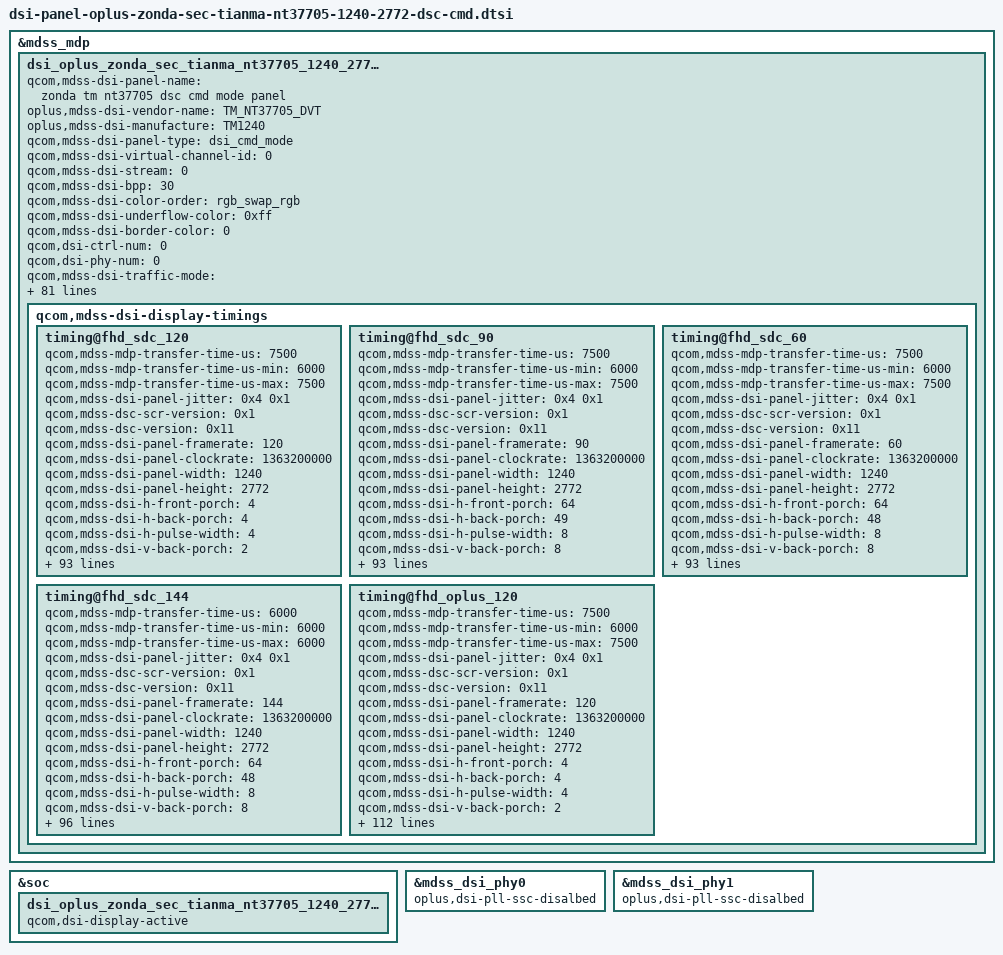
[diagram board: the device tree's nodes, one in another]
&mdss_mdp {
	dsi_oplus_zonda_sec_tianma_nt37705_1240_2772_dsc_cmd: qcom,mdss_dsi_oplus_zonda_sec_tianma_nt37705_1240_2772_dsc_cmd {
		qcom,mdss-dsi-panel-name = "zonda tm nt37705 dsc cmd mode panel";
		oplus,mdss-dsi-vendor-name = "TM_NT37705_DVT";
		oplus,mdss-dsi-manufacture = "TM1240";
		qcom,mdss-dsi-panel-type = "dsi_cmd_mode";
		qcom,mdss-dsi-virtual-channel-id = <0>;
		qcom,mdss-dsi-stream = <0>;
		qcom,mdss-dsi-bpp = <30>;
		qcom,mdss-dsi-color-order = "rgb_swap_rgb";
		qcom,mdss-dsi-underflow-color = <0xff>;
		qcom,mdss-dsi-border-color = <0>;
		qcom,dsi-ctrl-num = <0>;
		qcom,dsi-phy-num = <0>;
		qcom,mdss-dsi-traffic-mode = "non_burst_sync_event";
		qcom,mdss-dsi-lane-map = "lane_map_0123";
		qcom,mdss-dsi-bllp-eof-power-mode;
		qcom,mdss-dsi-bllp-power-mode;
		qcom,mdss-dsi-lane-0-state;
		qcom,mdss-dsi-lane-1-state;
		qcom,mdss-dsi-lane-2-state;
		qcom,mdss-dsi-lane-3-state;
		qcom,mdss-dsi-dma-trigger = "trigger_sw";
		qcom,mdss-dsi-mdp-trigger = "none";
		qcom,mdss-dsi-reset-sequence = <1 2>, <0 2>, <1 20>;

		qcom,mdss-dsi-te-pin-select = <1>;
		qcom,mdss-dsi-te-dcs-command = <1>;
		qcom,mdss-dsi-te-check-enable;
		qcom,mdss-dsi-te-using-te-pin;
		qcom,mdss-dsi-lp11-init;
		qcom,mdss-dsi-wr-mem-start = <0x2c>;
		qcom,mdss-dsi-wr-mem-continue = <0x3c>;
		/* HDR Setting */
		qcom,mdss-dsi-panel-hdr-enabled;
		qcom,mdss-dsi-panel-hdr-color-primaries = <15635 16450 34000 16000 13250 34500 7500 3000>;
		qcom,mdss-dsi-panel-peak-brightness = <5400000>;
		qcom,mdss-dsi-panel-blackness-level = <2000>;
		qcom,mdss-pan-physical-width-dimension = <70>;
		qcom,mdss-pan-physical-height-dimension = <156>;

		qcom,esd-check-enabled;
		//oplus,esd-check-flag-enabled;
		qcom,mdss-dsi-panel-status-check-mode = "reg_read";
		qcom,mdss-dsi-panel-status-command = [
				06 01 00 01 05 00 02 0A 00
			];
		qcom,mdss-dsi-panel-status-command-state = "dsi_lp_mode";
		qcom,mdss-dsi-panel-status-value = <0x9C>;
		qcom,mdss-dsi-panel-status-read-length = <1>;

		qcom,dynamic-mode-switch-enabled;
		qcom,dynamic-mode-switch-type = "dynamic-resolution-switch-immediate";
		qcom,mdss-dsi-display-timings {
				timing@fhd_sdc_120{
				qcom,mdss-mdp-transfer-time-us = <7500>;
				qcom,mdss-mdp-transfer-time-us-min = <6000>;
				qcom,mdss-mdp-transfer-time-us-max = <7500>;
				qcom,mdss-dsi-panel-jitter = <0x4 0x1>;
				qcom,mdss-dsc-scr-version = <0x1>;
				qcom,mdss-dsc-version = <0x11>;
				qcom,mdss-dsi-panel-framerate = <120>;
				qcom,mdss-dsi-panel-clockrate = <1363200000>;
				qcom,mdss-dsi-panel-width = <1240>;
				qcom,mdss-dsi-panel-height = <2772>;

				qcom,mdss-dsi-h-front-porch = <4>;
				qcom,mdss-dsi-h-back-porch = <4>;
				qcom,mdss-dsi-h-pulse-width = <4>;
				qcom,mdss-dsi-v-back-porch = <2>;
				qcom,mdss-dsi-v-front-porch = <2>;
				qcom,mdss-dsi-v-pulse-width = <2>;
				qcom,mdss-dsi-h-sync-pulse = <0>;

				qcom,mdss-dsi-h-left-border = <0>;
				qcom,mdss-dsi-h-right-border = <0>;
				qcom,mdss-dsi-v-top-border = <0>;
				qcom,mdss-dsi-v-bottom-border = <0>;

				/* Apollo vsync config, need to measure TE signal */
				//oplus,apollo-panel-vsync-width = <13000>;
				//oplus,apollo-panel-vsync-period = <16600>;

				/*SDC ADFR*/
				qcom,mdss-dsi-h-sync-skew = <0>;
				qcom,mdss-dsi-panel-vsync-source = <1>;
				qcom,mdss-dsi-qsync-min-fps-0 = <1314>;
				oplus,fod-on-vblank = <0>;
				oplus,fod-off-vblank = <0>;
				oplus,ofp-need-to-filter-backlight-dim-icon;
				qcom,mdss-dsi-bl-demura1-command = [
					/* 51hex > 0x644 */
					39 00 00 50 00 00 06 F0 55 AA 52 08 04
					39 00 00 50 00 00 02 6F 02
					39 00 00 50 00 00 03 EC 01 03
					39 00 00 50 00 00 02 6F A5
					39 00 00 10 00 00 07 EC 01 01 01 03 03 03
				];
				qcom,mdss-dsi-bl-demura2-command = [
					/* 0x644>51hex>=0x530 */
					39 00 00 50 00 00 06 F0 55 AA 52 08 04
					39 00 00 50 00 00 02 6F 02
					39 00 00 50 00 00 03 EC 03 0B
					39 00 00 50 00 00 02 6F A5
					39 00 00 10 00 00 07 EC 03 03 03 0B 0B 0B
				];
				qcom,mdss-dsi-bl-demura3-command = [
					/* 0x530>51hex>=0x33A */
					39 00 00 50 00 00 06 F0 55 AA 52 08 04
					39 00 00 50 00 00 02 6F 02
					39 00 00 50 00 00 03 EC 10 18
					39 00 00 50 00 00 02 6F A5
					39 00 00 10 00 00 07 EC 10 10 10 18 18 18
				];
				qcom,mdss-dsi-bl-demura4-command = [
					/* 0x339>51hex>=0x25C */
					39 00 00 50 00 00 06 F0 55 AA 52 08 04
					39 00 00 50 00 00 02 6F 02
					39 00 00 50 00 00 03 EC 15 1D
					39 00 00 50 00 00 02 6F A5
					39 00 00 10 00 00 07 EC 15 15 15 1D 1D 1D
				];
				qcom,mdss-dsi-bl-demura5-command = [
					/* 0x25C>51hex>=0x196 */
					39 00 00 50 00 00 06 F0 55 AA 52 08 04
					39 00 00 50 00 00 02 6F 02
					39 00 00 50 00 00 03 EC 15 2D
					39 00 00 50 00 00 02 6F A5
					39 00 00 10 00 00 07 EC 15 15 15 2D 2D 2D
				];
				qcom,mdss-dsi-bl-demura6-command = [
					/* 0x196>51hex>=0x008 */
					39 00 00 50 00 00 06 F0 55 AA 52 08 04
					39 00 00 50 00 00 02 6F 02
					39 00 00 50 00 00 03 EC 15 4D
					39 00 00 50 00 00 02 6F A5
					39 00 00 10 00 00 07 EC 15 15 15 4D 4D 4D
				];
				qcom,mdss-dsi-skipframe-dbv-command = [
					39 00 00 40 00 00 06 F0 55 AA 52 08 01
					39 00 00 40 00 00 02 6F 02
					39 00 00 40 00 00 11 E5 00 00 00 00 00 00 00 00 00 00 00 00 00 00 00 00
					39 00 00 40 00 00 02 6F 24
					39 00 00 40 00 00 0D E5 00 00 00 00 00 00 00 00 00 00 00 00
					39 00 00 40 00 00 02 6F 46
					39 00 00 40 00 00 0D E5 00 00 00 00 00 00 00 00 00 00 00 00
					39 00 00 40 00 00 02 6F 03
					39 00 00 40 00 00 19 C6 16 16 1F 23 23 23 23 23 23 23 23 21 23 23 23 23 23 23 18 18 21 23 23 23
					39 00 00 40 00 00 02 E5 B2
					39 00 00 40 00 00 02 6F 22
					39 00 00 40 00 00 02 E5 B2
					39 00 00 40 00 00 02 6F 44
					39 00 00 40 00 00 02 E5 B2
					39 00 00 40 00 00 06 F0 55 AA 52 08 05
					39 00 00 40 00 00 02 6F 12
					39 00 00 40 00 00 05 EC 00 00 00 00
					39 00 00 40 00 00 06 F0 55 AA 52 08 00
					39 00 00 40 00 00 02 6F 11
					39 00 00 40 00 00 04 B2 02 03 42
					39 00 00 00 00 00 03 51 03 FF
					];
				qcom,mdss-dsi-timing-switch-command = [
					/* switch */
					39 00 00 40 00 00 06 F0 55 AA 52 08 00
					39 00 00 00 0C 00 02 2F 00
					39 00 00 40 00 00 02 BE 47
					39 00 00 40 00 00 02 6F A8
					39 00 00 40 00 00 03 BA 00 00
					39 00 00 40 00 00 02 6F B0
					39 00 00 40 00 00 05 BA 00 00 00 00
					39 00 00 40 00 00 02 2F 30
					39 00 00 40 00 00 02 6D 00
					39 00 00 00 00 00 05 35 00 00 00 00
					];
				qcom,mdss-dsi-on-command=[
					/*Skip frame*/
					39 00 00 40 00 00 06 F0 55 AA 52 08 00
					39 00 00 40 00 00 02 6F 1B
					39 00 00 40 00 00 02 BA 18
					39 00 00 40 00 00 02 6F 1C
					39 00 00 40 00 00 11 BA 01 01 01 01 00 01 02 03 00 01 02 03 00 00 00 00
					39 00 00 40 00 00 02 6F 2C
					39 00 00 40 00 00 11 BA 01 01 01 01 00 01 02 03 00 01 02 03 00 00 00 00
					39 00 00 40 00 00 02 6F 3C
					39 00 00 40 00 00 11 BA 01 01 01 01 00 01 02 03 00 01 02 03 00 00 00 00
					39 00 00 40 00 00 02 6F 4C
					39 00 00 40 00 00 11 BA 01 01 01 01 00 01 02 03 00 01 02 03 00 00 00 00
					39 00 00 40 00 00 02 6F 5C
					39 00 00 40 00 00 05 BA 01 01 01 01
					39 00 00 40 00 00 02 6F 6C
					39 00 00 40 00 00 05 BA 00 01 02 03
					39 00 00 40 00 00 02 6F 7C
					39 00 00 40 00 00 05 BA 00 01 02 03
					39 00 00 40 00 00 02 6F 8C
					39 00 00 40 00 00 05 BA 00 00 00 00
					39 00 00 40 00 00 02 6F 9C
					39 00 00 40 00 00 09 BA 11 11 11 11 11 11 11 11
					39 00 00 40 00 00 02 6F A4
					39 00 00 40 00 00 03 BA E4 E4
					39 00 00 40 00 00 02 6F A8
					39 00 00 40 00 00 04 BA 00 00 00
					39 00 00 40 00 00 02 6F B0
					39 00 00 40 00 00 05 BA 00 00 00 00
					39 00 00 40 00 00 02 6F 08
					39 00 00 40 00 00 17 BB 01 00 00 00 01 00 00 00 01 00 00 00 01 00 00 00 01 00 00 00 00 00
					39 00 00 40 00 00 06 F0 55 AA 52 08 01
					39 00 00 40 00 00 13 E5 B2 22 00 00 00 00 20 20 20 20 24 24 24 24 00 00 00 00
					39 00 00 40 00 00 02 6F 22
					39 00 00 40 00 00 13 E5 B2 22 00 00 00 00 20 20 20 20 24 24 24 24 00 00 00 00
					39 00 00 40 00 00 02 6F 44
					39 00 00 40 00 00 13 E5 B2 22 00 00 00 00 20 20 20 20 24 24 24 24 00 00 00 00
					39 00 00 40 00 00 02 6F 66
					39 00 00 40 00 00 13 E5 B2 22 00 00 00 00 20 20 20 20 24 24 24 24 00 00 00 00
					39 00 00 40 00 00 02 6F 0C
					39 00 00 40 00 00 03 CE 0D 11
					39 00 00 40 00 00 02 6F 27
					39 00 00 40 00 00 06 B9 AA AA AA 00 00
					39 00 00 40 00 00 02 6F 03
					39 00 00 40 00 00 07 C6 16 16 16 23 23 23
					39 00 00 40 00 00 02 6F 0C
					39 00 00 40 00 00 07 C6 16 16 16 23 23 23
					39 00 00 40 00 00 02 6F 15
					39 00 00 40 00 00 07 C6 16 16 16 23 23 23
					39 00 00 40 00 00 02 6F 1E
					39 00 00 40 00 00 07 C6 16 16 16 23 23 23
					39 00 00 40 00 00 06 F0 55 AA 52 08 00
					39 00 00 40 00 00 02 6F 13
					39 00 00 40 00 00 02 C2 D8
					39 00 00 40 00 00 06 F0 55 AA 52 08 05
					39 00 00 40 00 00 02 6F 12
					39 00 00 40 00 00 05 EC 00 00 00 00
					/* Optimize edge green */
					/*39 00 00 40 00 00 06 F0 55 AA 52 08 07*/
					/*39 00 00 40 00 00 0E B4 C0 80 80 80 80 50 80 80 80 80 80 50 80*/
					/* Vsync Hsync output */
					39 00 00 40 00 00 06 F0 55 AA 52 08 00
					39 00 00 40 00 00 02 6F 02
					39 00 00 00 00 00 03 BE 49 4C
					/* AVDD=7.9 */
					/* 39 00 00 40 00 00 06 F0 55 AA 52 08 00 */
					/* 39 00 00 40 00 00 02 6F 07 */
					/* 39 00 00 40 00 00 02 B5 4E */
					/* HBM L0 glows green */
					39 00 00 40 00 00 02 B5 80
					39 00 00 40 00 00 02 6F 2C
					39 00 00 00 00 00 02 B5 03
					39 00 00 40 00 00 05 FF AA 55 A5 81
					39 00 00 40 00 00 02 6F 19
					39 00 00 40 00 00 02 FB 00
					39 00 00 40 00 00 02 6F 05
					39 00 00 40 00 00 02 FE 34
					39 00 00 40 00 00 05 FF AA 55 A5 80
					39 00 00 40 00 00 02 6F 1A
					39 00 00 40 00 00 02 F4 55
					39 00 00 40 00 00 05 FF AA 55 A5 83
					39 00 00 40 00 00 02 6F 12
					39 00 00 40 00 00 02 FE 41
					39 00 00 40 00 00 02 5F 00
					39 00 00 40 00 00 02 26 00
					39 00 00 40 00 00 02 26 00
					39 00 00 40 00 00 02 17 10
					39 00 00 40 00 00 05 2A 00 00 04 D7
					39 00 00 00 00 00 05 2B 00 00 0A D3
					/* Fre 120Hz */
					39 00 00 00 00 00 02 2F 00
					/* TE ON */
					39 00 00 40 00 00 02 35 00
					39 00 00 00 00 00 03 44 00 00
					/* Nor 51 */
					39 00 00 40 00 00 03 51 00 00
					39 00 00 00 00 00 02 6F 04
					/* AOD 51 */
					39 00 00 40 00 00 03 51 00 00
					39 00 00 40 00 00 02 53 20
					39 00 00 00 00 00 03 90 03 03
					/* 10bit DSC */
					39 00 00 40 00 00 13 91 AB 28 00 0C F2 00 02 85 01 0F 00 08 0A E9 07 5F 10 F0
					39 00 00 40 00 00 05 FF AA 55 A5 81
					39 00 00 40 00 00 02 6F 24
					39 00 00 40 00 00 15 FB 00 03 04 55 77 77 77 99 9D 00 00 06 88 9A BB BC DE EF F0 11
					39 00 00 40 00 00 05 FF AA 55 A5 81
					39 00 00 40 00 00 02 6F 0E
					39 00 00 40 00 00 02 F5 00
					39 00 00 40 00 00 05 FF AA 55 A5 80
					39 00 00 40 00 00 02 6F 0F
					39 00 00 40 00 00 02 FC 00
					39 00 00 40 00 00 02 6F 09
					39 00 00 40 00 00 03 FC FC F0
					39 00 00 40 00 00 05 FF AA 55 A5 80
					39 00 00 40 00 00 02 6F 0A
					39 00 00 40 00 00 04 F6 70 70 70
					39 00 00 40 00 00 02 6F 0E
					39 00 00 00 00 00 02 F6 60
					/* OSC start */
					39 00 00 40 00 00 05 FF AA 55 A5 80
					39 00 00 40 00 00 02 6F 11
					/* OSC2 145Mhz */
					39 00 00 40 00 00 03 F8 01 8E
					39 00 00 40 00 00 02 6F 2D
					/* OSC1 121.9Mhz */
					39 00 00 40 00 00 03 F8 00 FC
					39 00 00 40 00 00 02 6F 01
					39 00 00 40 00 00 02 1F 06
					39 00 00 40 00 00 05 FF AA 55 A5 81
					39 00 00 40 00 00 02 6F 1E
					39 00 00 00 00 00 02 FB 0F
					/* OSC end */
					39 00 00 40 00 00 05 FF AA 55 A5 83
					39 00 00 40 00 00 02 6F 12
					39 00 00 40 00 00 02 FE 41
					39 00 00 40 00 00 05 FF AA 55 A5 80
					39 00 00 40 00 00 02 6F 19
					39 00 00 40 00 00 02 F2 00
					39 00 00 40 00 00 05 FF AA 55 A5 81
					39 00 00 40 00 00 02 6F 02
					39 00 00 40 00 00 02 F9 04
					39 00 00 40 00 00 02 5A 00
					/* AOD remove black frame */
					39 00 00 00 00 00 06 F0 55 AA 52 08 01
					39 00 00 00 00 00 06 D2 00 00 00 00 15
					15 00 00 00 00 00 02 6F 05
					39 00 00 00 00 00 04 D2 01 00 00
					15 00 00 00 00 00 02 6F 0E
					39 00 00 00 00 00 06 D2 02 00 10 05 88
					39 00 00 00 00 00 0B E4 80 00 00 00 00 00 00 00 00 33
					15 00 00 00 00 00 02 6F 0A
					39 00 00 00 00 00 07 E4 80 00 00 10 00 53
					/* AOD off splash */
					39 00 00 40 00 00 06 F0 55 AA 52 08 01
					39 00 00 40 00 00 02 6F 0E
					39 00 00 00 00 00 06 D2 02 00 10 05 82
					/* 11H sleep out */
					39 00 00 00 80 00 02 11 00
					39 00 00 40 00 00 06 F0 55 AA 52 08 00
					39 00 00 00 11 00 02 2F 00
					39 00 00 40 00 00 02 BE 47
					39 00 00 40 00 00 02 6F A8
					39 00 00 40 00 00 03 BA 00 00
					39 00 00 40 00 00 02 6F B0
					39 00 00 40 00 00 05 BA 00 00 00 00
					39 00 00 40 00 00 02 2F 30
					39 00 00 40 00 00 02 6D 00
					39 00 00 00 00 00 05 35 00 00 00 00
					05 00 00 00 00 00 01 29
					/* OSC Tracking for 60/90/120 fps */
					39 00 00 40 00 00 06 F0 55 AA 52 08 01
					39 00 00 00 11 00 2A C3 DD 06 22 15 F9 00 06 20 15 FF 00 03 E7 16 06 2B 1D 03 E7 16 06 2B 1D 03 E7 16 06 2B 1D 03 E7 16 06 2B 1D 03 E7 16 06 2B 1D
				];

				qcom,mdss-dsi-panel-info-switch-page-command = [
					/*read panel info switch page 01*/
					39 00 00 00 00 00 06 F0 55 AA 52 08 01
				];
				qcom,mdss-dsi-default-switch-page-command = [
					/*switch default page*/
					39 00 00 00 00 00 06 F0 55 AA 52 08 00
				];

				qcom,mdss-dsi-qsync-min-fps-0-command = [
					/* SDC Auto Off */
					15 00 00 40 00 00 02 2F 00
					15 00 00 40 00 00 02 2F 30
					15 00 00 00 00 00 02 6D 00
				];

				qcom,mdss-dsi-post-on-backlight = [
					/* Display On */
					05 00 00 00 00 00 01 29
				];
				qcom,mdss-dsi-off-command=[
					05 00 00 00 0A 00 01 28
					05 00 00 00 78 00 01 10
				];
				qcom,mdss-dsi-lp1-command = [
					/* AOD Mode ON Setting */
					39 00 00 00 00 00 06 F0 55 AA 52 08 00
					15 00 00 00 00 00 02 6F 0C
					39 00 00 00 00 00 03 B5 50 4B
					39 00 00 00 00 00 05 35 00 00 00 00
					39 00 00 00 00 00 03 44 00 00
					15 00 00 00 00 00 02 2F 00
					05 00 00 00 00 00 01 39
					15 00 00 00 00 00 02 65 01
					15 00 00 00 00 00 02 6F 04
					39 00 00 00 00 00 03 51 02 FF
				];
				qcom,mdss-dsi-nolp-command = [
					/* AOD OFF */
					39 00 00 00 00 00 06 F0 55 AA 52 08 00
					15 00 00 00 00 00 02 6F 0C
					39 00 00 00 00 00 03 B5 4F 4B
					15 00 00 00 00 00 02 65 00
					05 00 00 00 00 00 01 38
					15 00 00 00 00 00 02 2F 30
					15 00 00 00 00 00 02 6D 00
					39 00 00 00 00 00 05 35 00 00 00 00
					39 00 00 00 00 00 03 44 00 00
					39 00 00 00 28 00 03 51 00 00
				];
				qcom,mdss-dsi-hbm-off-command = [
					//39 00 00 00 00 00 03 51 0D BB
				];
				qcom,mdss-dsi-hbm-on-command = [
					39 00 00 40 00 00 06 F0 55 AA 52 08 04
					39 00 00 40 00 00 02 6F 02
					39 00 00 40 00 00 03 EC 01 03
					39 00 00 40 00 00 02 6F A5
					39 00 00 00 00 00 07 EC 01 01 01 03 03 03
					39 00 00 40 00 00 06 F0 55 AA 52 08 01
					39 00 00 40 00 00 02 6F 02
					39 00 00 40 00 00 09 E5 00 00 00 00 20 20 20 00
					39 00 00 40 00 00 02 6F 46
					39 00 00 40 00 00 0D E5 00 00 00 00 20 20 20 00 28 28 28 00
					39 00 00 40 00 00 02 6F 03
					39 00 00 40 00 00 19 C6 37 37 37 23 23 23 23 23 23 23 23 23 23 23 23 23 23 23 37 37 37 23 23 23
					39 00 00 40 00 00 02 E5 B2
					39 00 00 40 00 00 02 6F 44
					39 00 00 40 00 00 02 E5 B2
					39 00 00 40 00 00 06 F0 55 AA 52 08 05
					39 00 00 40 00 00 02 6F 12
					39 00 00 40 00 00 05 EC 00 00 00 00
					39 00 00 40 00 00 06 F0 55 AA 52 08 00
					39 00 00 40 00 00 02 6F 11
					39 00 00 40 00 00 04 B2 02 03 42
					39 00 00 00 00 00 03 51 0F 00
				];
				qcom,mdss-dsi-aod-high-mode-command = [
					/* AOD 50nit */
					15 00 00 40 00 00 02 6F 04
					39 00 00 00 00 00 03 51 02 FF
				];
				qcom,mdss-dsi-aod-low-mode-command = [
					/* AOD 10nit */
					15 00 00 40 00 00 02 6F 04
					39 00 00 00 00 00 03 51 01 FF
				];
				qcom,mdss-dsi-timing-switch-command-state = "dsi_hs_mode";
				qcom,mdss-dsi-on-command-state = "dsi_lp_mode";
				qcom,mdss-dsi-off-command-state = "dsi_hs_mode";
				qcom,mdss-dsi-hbm-on-command-state = "dsi_lp_mode";
				qcom,mdss-dsi-hbm-off-command-state = "dsi_lp_mode";
				qcom,mdss-dsi-skipframe-dbv-command-state = "dsi_hs_mode";
				qcom,mdss-dsi-qsync-min-fps-0-command-state = "dsi_hs_mode";
				qcom,mdss-dsi-bl-demura1-command-state = "dsi_hs_mode";
				qcom,mdss-dsi-bl-demura2-command-state = "dsi_hs_mode";
				qcom,mdss-dsi-bl-demura3-command-state = "dsi_hs_mode";
				qcom,mdss-dsi-bl-demura4-command-state = "dsi_hs_mode";
				qcom,mdss-dsi-bl-demura5-command-state = "dsi_hs_mode";
				qcom,mdss-dsi-bl-demura6-command-state = "dsi_hs_mode";
				qcom,mdss-dsi-panel-info-switch-page-command-state = "dsi_lp_mode";
				qcom,mdss-dsi-default-switch-page-command-state = "dsi_lp_mode";

				qcom,lm-split = <620 620>;
				qcom,compression-mode = "dsc";
				qcom,mdss-dsc-encoders = <2>;
				qcom,mdss-dsc-slice-height = <12>;
				qcom,mdss-dsc-slice-width = <620>;
				qcom,mdss-dsc-slice-per-pkt = <2>;
				qcom,mdss-dsc-bit-per-component = <10>;
				qcom,mdss-dsc-bit-per-pixel = <8>;
				qcom,mdss-dsc-block-prediction-enable;
			};
			timing@fhd_sdc_90{
				qcom,mdss-mdp-transfer-time-us = <7500>;
				qcom,mdss-mdp-transfer-time-us-min = <6000>;
				qcom,mdss-mdp-transfer-time-us-max = <7500>;
				qcom,mdss-dsi-panel-jitter = <0x4 0x1>;
				qcom,mdss-dsc-scr-version = <0x1>;
				qcom,mdss-dsc-version = <0x11>;
				qcom,mdss-dsi-panel-framerate = <90>;
				qcom,mdss-dsi-panel-clockrate = <1363200000>;
				qcom,mdss-dsi-panel-width = <1240>;
				qcom,mdss-dsi-panel-height = <2772>;

				qcom,mdss-dsi-h-front-porch = <64>;
				qcom,mdss-dsi-h-back-porch = <49>;
				qcom,mdss-dsi-h-pulse-width = <8>;
				qcom,mdss-dsi-v-back-porch = <8>;
				qcom,mdss-dsi-v-front-porch = <2>;
				qcom,mdss-dsi-v-pulse-width = <2>;
				qcom,mdss-dsi-h-sync-pulse = <0>;

				qcom,mdss-dsi-h-left-border = <0>;
				qcom,mdss-dsi-h-right-border = <0>;
				qcom,mdss-dsi-v-top-border = <0>;
				qcom,mdss-dsi-v-bottom-border = <0>;

				/* Apollo vsync config, need to measure TE signal */
				//oplus,apollo-panel-vsync-width = <13000>;
				//oplus,apollo-panel-vsync-period = <16600>;

				qcom,mdss-dsi-h-sync-skew = <0>;
				qcom,mdss-dsi-panel-vsync-source = <1>;
				qcom,mdss-dsi-qsync-min-fps-0 = <1314>;
				oplus,fod-on-vblank = <0>;
				oplus,fod-off-vblank = <0>;
				oplus,ofp-need-to-filter-backlight-dim-icon;
				qcom,mdss-dsi-bl-demura1-command = [
					/* 51hex > 0x644 */
					39 00 00 50 00 00 06 F0 55 AA 52 08 04
					39 00 00 50 00 00 02 6F 02
					39 00 00 50 00 00 03 EC 01 03
					39 00 00 50 00 00 02 6F A5
					39 00 00 10 00 00 07 EC 01 01 01 03 03 03
				];
				qcom,mdss-dsi-bl-demura2-command = [
					/* 0x644>51hex>=0x530 */
					39 00 00 50 00 00 06 F0 55 AA 52 08 04
					39 00 00 50 00 00 02 6F 02
					39 00 00 50 00 00 03 EC 03 0B
					39 00 00 50 00 00 02 6F A5
					39 00 00 10 00 00 07 EC 03 03 03 0B 0B 0B
				];
				qcom,mdss-dsi-bl-demura3-command = [
					/* 0x530>51hex>=0x33A */
					39 00 00 50 00 00 06 F0 55 AA 52 08 04
					39 00 00 50 00 00 02 6F 02
					39 00 00 50 00 00 03 EC 10 18
					39 00 00 50 00 00 02 6F A5
					39 00 00 10 00 00 07 EC 10 10 10 18 18 18
				];
				qcom,mdss-dsi-bl-demura4-command = [
					/* 0x339>51hex>=0x25C */
					39 00 00 50 00 00 06 F0 55 AA 52 08 04
					39 00 00 50 00 00 02 6F 02
					39 00 00 50 00 00 03 EC 15 1D
					39 00 00 50 00 00 02 6F A5
					39 00 00 10 00 00 07 EC 15 15 15 1D 1D 1D
				];
				qcom,mdss-dsi-bl-demura5-command = [
					/* 0x25C>51hex>=0x196 */
					39 00 00 50 00 00 06 F0 55 AA 52 08 04
					39 00 00 50 00 00 02 6F 02
					39 00 00 50 00 00 03 EC 15 2D
					39 00 00 50 00 00 02 6F A5
					39 00 00 10 00 00 07 EC 15 15 15 2D 2D 2D
				];
				qcom,mdss-dsi-bl-demura6-command = [
					/* 0x196>51hex>=0x008 */
					39 00 00 50 00 00 06 F0 55 AA 52 08 04
					39 00 00 50 00 00 02 6F 02
					39 00 00 50 00 00 03 EC 15 4D
					39 00 00 50 00 00 02 6F A5
					39 00 00 10 00 00 07 EC 15 15 15 4D 4D 4D
				];
				qcom,mdss-dsi-skipframe-dbv-command = [
					39 00 00 40 00 00 06 F0 55 AA 52 08 01
					39 00 00 40 00 00 02 6F 02
					39 00 00 40 00 00 11 E5 00 00 00 00 00 00 00 00 00 00 00 00 00 00 00 00
					39 00 00 40 00 00 02 6F 24
					39 00 00 40 00 00 0D E5 00 00 00 00 00 00 00 00 00 00 00 00
					39 00 00 40 00 00 02 6F 46
					39 00 00 40 00 00 0D E5 00 00 00 00 00 00 00 00 00 00 00 00
					39 00 00 40 00 00 02 6F 03
					39 00 00 40 00 00 19 C6 16 16 1F 23 23 23 23 23 23 23 23 21 23 23 23 23 23 23 18 18 21 23 23 23
					39 00 00 40 00 00 02 E5 B2
					39 00 00 40 00 00 02 6F 22
					39 00 00 40 00 00 02 E5 B2
					39 00 00 40 00 00 02 6F 44
					39 00 00 40 00 00 02 E5 B2
					39 00 00 40 00 00 06 F0 55 AA 52 08 05
					39 00 00 40 00 00 02 6F 12
					39 00 00 40 00 00 05 EC 00 00 00 00
					39 00 00 40 00 00 06 F0 55 AA 52 08 00
					39 00 00 40 00 00 02 6F 11
					39 00 00 40 00 00 04 B2 02 03 42
					39 00 00 00 00 00 03 51 03 FF
					];
				qcom,mdss-dsi-timing-switch-command = [
					/* switch */
					39 00 00 40 00 00 06 F0 55 AA 52 08 00
					39 00 00 00 0C 00 02 2F 01
					39 00 00 40 00 00 02 BE 47
					39 00 00 40 00 00 02 6F A8
					39 00 00 40 00 00 03 BA 11 11
					39 00 00 40 00 00 02 6F B0
					39 00 00 40 00 00 05 BA 11 11 00 00
					39 00 00 40 00 00 02 2F 31
					39 00 00 40 00 00 02 6D 00
					39 00 00 00 00 00 05 35 00 00 00 00
					];
				qcom,mdss-dsi-on-command=[
					/*Skip frame*/
					39 00 00 40 00 00 06 F0 55 AA 52 08 00
					39 00 00 40 00 00 02 6F 1B
					39 00 00 40 00 00 02 BA 18
					39 00 00 40 00 00 02 6F 1C
					39 00 00 40 00 00 11 BA 01 01 01 01 00 01 02 03 00 01 02 03 00 00 00 00
					39 00 00 40 00 00 02 6F 2C
					39 00 00 40 00 00 11 BA 01 01 01 01 00 01 02 03 00 01 02 03 00 00 00 00
					39 00 00 40 00 00 02 6F 3C
					39 00 00 40 00 00 11 BA 01 01 01 01 00 01 02 03 00 01 02 03 00 00 00 00
					39 00 00 40 00 00 02 6F 4C
					39 00 00 40 00 00 11 BA 01 01 01 01 00 01 02 03 00 01 02 03 00 00 00 00
					39 00 00 40 00 00 02 6F 5C
					39 00 00 40 00 00 05 BA 01 01 01 01
					39 00 00 40 00 00 02 6F 6C
					39 00 00 40 00 00 05 BA 00 01 02 03
					39 00 00 40 00 00 02 6F 7C
					39 00 00 40 00 00 05 BA 00 01 02 03
					39 00 00 40 00 00 02 6F 8C
					39 00 00 40 00 00 05 BA 00 00 00 00
					39 00 00 40 00 00 02 6F 9C
					39 00 00 40 00 00 09 BA 11 11 11 11 11 11 11 11
					39 00 00 40 00 00 02 6F A4
					39 00 00 40 00 00 03 BA E4 E4
					39 00 00 40 00 00 02 6F A8
					39 00 00 40 00 00 04 BA 00 00 00
					39 00 00 40 00 00 02 6F B0
					39 00 00 40 00 00 05 BA 00 00 00 00
					39 00 00 40 00 00 02 6F 08
					39 00 00 40 00 00 17 BB 01 00 00 00 01 00 00 00 01 00 00 00 01 00 00 00 01 00 00 00 00 00
					39 00 00 40 00 00 06 F0 55 AA 52 08 01
					39 00 00 40 00 00 13 E5 B2 22 00 00 00 00 20 20 20 20 24 24 24 24 00 00 00 00
					39 00 00 40 00 00 02 6F 22
					39 00 00 40 00 00 13 E5 B2 22 00 00 00 00 20 20 20 20 24 24 24 24 00 00 00 00
					39 00 00 40 00 00 02 6F 44
					39 00 00 40 00 00 13 E5 B2 22 00 00 00 00 20 20 20 20 24 24 24 24 00 00 00 00
					39 00 00 40 00 00 02 6F 66
					39 00 00 40 00 00 13 E5 B2 22 00 00 00 00 20 20 20 20 24 24 24 24 00 00 00 00
					39 00 00 40 00 00 02 6F 0C
					39 00 00 40 00 00 03 CE 0D 11
					39 00 00 40 00 00 02 6F 27
					39 00 00 40 00 00 06 B9 AA AA AA 00 00
					39 00 00 40 00 00 02 6F 03
					39 00 00 40 00 00 07 C6 16 16 16 23 23 23
					39 00 00 40 00 00 02 6F 0C
					39 00 00 40 00 00 07 C6 16 16 16 23 23 23
					39 00 00 40 00 00 02 6F 15
					39 00 00 40 00 00 07 C6 16 16 16 23 23 23
					39 00 00 40 00 00 02 6F 1E
					39 00 00 40 00 00 07 C6 16 16 16 23 23 23
					39 00 00 40 00 00 06 F0 55 AA 52 08 00
					39 00 00 40 00 00 02 6F 13
					39 00 00 40 00 00 02 C2 D8
					39 00 00 40 00 00 06 F0 55 AA 52 08 05
					39 00 00 40 00 00 02 6F 12
					39 00 00 40 00 00 05 EC 00 00 00 00
					/* Optimize edge green */
					/*39 00 00 40 00 00 06 F0 55 AA 52 08 07*/
					/*39 00 00 40 00 00 0E B4 C0 80 80 80 80 50 80 80 80 80 80 50 80*/
					/* Vsync Hsync output */
					39 00 00 40 00 00 06 F0 55 AA 52 08 00
					39 00 00 40 00 00 02 6F 02
					39 00 00 00 00 00 03 BE 49 4C
					/* AVDD=7.9 */
					/* 39 00 00 40 00 00 06 F0 55 AA 52 08 00 */
					/* 39 00 00 40 00 00 02 6F 07 */
					/* 39 00 00 40 00 00 02 B5 4E */
					/* HBM L0 glows green */
					39 00 00 40 00 00 02 B5 80
					39 00 00 40 00 00 02 6F 2C
					39 00 00 00 00 00 02 B5 03
					39 00 00 40 00 00 05 FF AA 55 A5 81
					39 00 00 40 00 00 02 6F 19
					39 00 00 40 00 00 02 FB 00
					39 00 00 40 00 00 02 6F 05
					39 00 00 40 00 00 02 FE 34
					39 00 00 40 00 00 05 FF AA 55 A5 80
					39 00 00 40 00 00 02 6F 1A
					39 00 00 40 00 00 02 F4 55
					39 00 00 40 00 00 05 FF AA 55 A5 83
					39 00 00 40 00 00 02 6F 12
					39 00 00 40 00 00 02 FE 41
					39 00 00 40 00 00 02 5F 00
					39 00 00 40 00 00 02 26 00
					39 00 00 40 00 00 02 26 00
					39 00 00 40 00 00 02 17 10
					39 00 00 40 00 00 05 2A 00 00 04 D7
					39 00 00 00 00 00 05 2B 00 00 0A D3
					/* Fre 90Hz */
					39 00 00 00 00 00 02 2F 01
					/* TE ON */
					39 00 00 40 00 00 02 35 00
					39 00 00 00 00 00 03 44 00 00
					/* Nor 51 */
					39 00 00 40 00 00 03 51 00 00
					39 00 00 00 00 00 02 6F 04
					/* AOD 51 */
					39 00 00 40 00 00 03 51 00 00
					39 00 00 40 00 00 02 53 20
					39 00 00 00 00 00 03 90 03 03
					/* 10bit DSC */
					39 00 00 40 00 00 13 91 AB 28 00 0C F2 00 02 85 01 0F 00 08 0A E9 07 5F 10 F0
					39 00 00 40 00 00 05 FF AA 55 A5 81
					39 00 00 40 00 00 02 6F 24
					39 00 00 40 00 00 15 FB 00 03 04 55 77 77 77 99 9D 00 00 06 88 9A BB BC DE EF F0 11
					39 00 00 40 00 00 05 FF AA 55 A5 81
					39 00 00 40 00 00 02 6F 0E
					39 00 00 40 00 00 02 F5 00
					39 00 00 40 00 00 05 FF AA 55 A5 80
					39 00 00 40 00 00 02 6F 0F
					39 00 00 40 00 00 02 FC 00
					39 00 00 40 00 00 02 6F 09
					39 00 00 40 00 00 03 FC FC F0
					39 00 00 40 00 00 05 FF AA 55 A5 80
					39 00 00 40 00 00 02 6F 0A
					39 00 00 40 00 00 04 F6 70 70 70
					39 00 00 40 00 00 02 6F 0E
					39 00 00 00 00 00 02 F6 60
					/* OSC start */
					39 00 00 40 00 00 05 FF AA 55 A5 80
					39 00 00 40 00 00 02 6F 11
					/* OSC2 145Mhz */
					39 00 00 40 00 00 03 F8 01 8E
					39 00 00 40 00 00 02 6F 2D
					/* OSC1 121.9Mhz */
					39 00 00 40 00 00 03 F8 00 FC
					39 00 00 40 00 00 02 6F 01
					39 00 00 40 00 00 02 1F 06
					39 00 00 40 00 00 05 FF AA 55 A5 81
					39 00 00 40 00 00 02 6F 1E
					39 00 00 00 00 00 02 FB 0F
					/* OSC end */
					39 00 00 40 00 00 05 FF AA 55 A5 83
					39 00 00 40 00 00 02 6F 12
					39 00 00 40 00 00 02 FE 41
					39 00 00 40 00 00 05 FF AA 55 A5 80
					39 00 00 40 00 00 02 6F 19
					39 00 00 40 00 00 02 F2 00
					39 00 00 40 00 00 05 FF AA 55 A5 81
					39 00 00 40 00 00 02 6F 02
					39 00 00 40 00 00 02 F9 04
					39 00 00 40 00 00 02 5A 00
					/* AOD remove black frame */
					39 00 00 00 00 00 06 F0 55 AA 52 08 01
					39 00 00 00 00 00 06 D2 00 00 00 00 15
					15 00 00 00 00 00 02 6F 05
					39 00 00 00 00 00 04 D2 01 00 00
					15 00 00 00 00 00 02 6F 0E
					39 00 00 00 00 00 06 D2 02 00 10 05 88
					39 00 00 00 00 00 0B E4 80 00 00 00 00 00 00 00 00 33
					15 00 00 00 00 00 02 6F 0A
					39 00 00 00 00 00 07 E4 80 00 00 10 00 53
					/* AOD off splash */
					39 00 00 40 00 00 06 F0 55 AA 52 08 01
					39 00 00 40 00 00 02 6F 0E
					39 00 00 00 00 00 06 D2 02 00 10 05 82
					/* 11H sleep out */
					39 00 00 00 80 00 02 11 00
					39 00 00 40 00 00 06 F0 55 AA 52 08 00
					39 00 00 00 0C 00 02 2F 01
					39 00 00 40 00 00 02 BE 47
					39 00 00 40 00 00 02 6F A8
					39 00 00 40 00 00 03 BA 11 11
					39 00 00 40 00 00 02 6F B0
					39 00 00 40 00 00 05 BA 11 11 00 00
					39 00 00 40 00 00 02 2F 31
					39 00 00 40 00 00 02 6D 00
					39 00 00 00 00 00 05 35 00 00 00 00
					05 00 00 00 00 00 01 29
					/* OSC Tracking for 60/90/120 fps */
					39 00 00 40 00 00 06 F0 55 AA 52 08 01
					39 00 00 00 11 00 2A C3 DD 06 22 15 F9 00 06 20 15 FF 00 03 E7 16 06 2B 1D 03 E7 16 06 2B 1D 03 E7 16 06 2B 1D 03 E7 16 06 2B 1D 03 E7 16 06 2B 1D
				];

				qcom,mdss-dsi-panel-info-switch-page-command = [
					/*read panel info switch page 01*/
					39 00 00 00 00 00 06 F0 55 AA 52 08 01
				];
				qcom,mdss-dsi-default-switch-page-command = [
					/*switch default page*/
					39 00 00 00 00 00 06 F0 55 AA 52 08 00
				];

				qcom,mdss-dsi-qsync-min-fps-0-command = [
					/* SDC Auto Off */
					15 00 00 40 00 00 02 2F 01
					15 00 00 40 00 00 02 2F 31
					15 00 00 00 00 00 02 6D 00
				];

				qcom,mdss-dsi-post-on-backlight = [
					/* Display On */
					05 00 00 00 00 00 01 29
				];
				qcom,mdss-dsi-off-command=[
					05 00 00 00 0A 00 01 28
					05 00 00 00 78 00 01 10
				];
				qcom,mdss-dsi-lp1-command = [
					/* AOD Mode ON Setting */
					39 00 00 00 00 00 06 F0 55 AA 52 08 00
					15 00 00 00 00 00 02 6F 0C
					39 00 00 00 00 00 03 B5 50 4B
					39 00 00 00 00 00 05 35 00 00 00 00
					39 00 00 00 00 00 03 44 00 00
					15 00 00 00 00 00 02 2F 00
					05 00 00 00 00 00 01 39
					15 00 00 00 00 00 02 65 01
					15 00 00 00 00 00 02 6F 04
					39 00 00 00 00 00 03 51 02 FF
				];
				qcom,mdss-dsi-nolp-command = [
					/* AOD OFF */
					39 00 00 00 00 00 06 F0 55 AA 52 08 00
					15 00 00 00 00 00 02 6F 0C
					39 00 00 00 00 00 03 B5 4F 4B
					15 00 00 00 00 00 02 65 00
					05 00 00 00 00 00 01 38
					15 00 00 00 00 00 02 2F 31
					15 00 00 00 00 00 02 6D 00
					39 00 00 00 00 00 05 35 00 00 00 00
					39 00 00 00 00 00 03 44 00 00
					39 00 00 00 28 00 03 51 00 00
				];
				qcom,mdss-dsi-hbm-off-command = [
					//39 00 00 00 00 00 03 51 0D BB
				];
				qcom,mdss-dsi-hbm-on-command = [
					39 00 00 40 00 00 06 F0 55 AA 52 08 04
					39 00 00 40 00 00 02 6F 02
					39 00 00 40 00 00 03 EC 01 03
					39 00 00 40 00 00 02 6F A5
					39 00 00 00 00 00 07 EC 01 01 01 03 03 03
					39 00 00 40 00 00 06 F0 55 AA 52 08 01
					39 00 00 40 00 00 02 6F 02
					39 00 00 40 00 00 09 E5 00 00 00 00 20 20 20 00
					39 00 00 40 00 00 02 6F 46
					39 00 00 40 00 00 0D E5 00 00 00 00 20 20 20 00 28 28 28 00
					39 00 00 40 00 00 02 6F 03
					39 00 00 40 00 00 19 C6 37 37 37 23 23 23 23 23 23 23 23 23 23 23 23 23 23 23 37 37 37 23 23 23
					39 00 00 40 00 00 02 E5 B2
					39 00 00 40 00 00 02 6F 44
					39 00 00 40 00 00 02 E5 B2
					39 00 00 40 00 00 06 F0 55 AA 52 08 05
					39 00 00 40 00 00 02 6F 12
					39 00 00 40 00 00 05 EC 00 00 00 00
					39 00 00 40 00 00 06 F0 55 AA 52 08 00
					39 00 00 40 00 00 02 6F 11
					39 00 00 40 00 00 04 B2 02 03 42
					39 00 00 00 00 00 03 51 0F 00
				];
				qcom,mdss-dsi-aod-high-mode-command = [
					/* AOD 50nit */
					15 00 00 40 00 00 02 6F 04
					39 00 00 00 00 00 03 51 02 FF
				];
				qcom,mdss-dsi-aod-low-mode-command = [
					/* AOD 10nit */
					15 00 00 40 00 00 02 6F 04
					39 00 00 00 00 00 03 51 01 FF
				];
				qcom,mdss-dsi-timing-switch-command-state = "dsi_hs_mode";
				qcom,mdss-dsi-on-command-state = "dsi_lp_mode";
				qcom,mdss-dsi-off-command-state = "dsi_hs_mode";
				qcom,mdss-dsi-hbm-on-command-state = "dsi_lp_mode";
				qcom,mdss-dsi-hbm-off-command-state = "dsi_lp_mode";
				qcom,mdss-dsi-skipframe-dbv-command-state = "dsi_hs_mode";
				qcom,mdss-dsi-qsync-min-fps-0-command-state = "dsi_hs_mode";
				qcom,mdss-dsi-bl-demura1-command-state = "dsi_hs_mode";
				qcom,mdss-dsi-bl-demura2-command-state = "dsi_hs_mode";
				qcom,mdss-dsi-bl-demura3-command-state = "dsi_hs_mode";
				qcom,mdss-dsi-bl-demura4-command-state = "dsi_hs_mode";
				qcom,mdss-dsi-bl-demura5-command-state = "dsi_hs_mode";
				qcom,mdss-dsi-bl-demura6-command-state = "dsi_hs_mode";
				qcom,mdss-dsi-panel-info-switch-page-command-state = "dsi_lp_mode";
				qcom,mdss-dsi-default-switch-page-command-state = "dsi_lp_mode";

				qcom,lm-split = <620 620>;
				qcom,compression-mode = "dsc";
				qcom,mdss-dsc-encoders = <2>;
				qcom,mdss-dsc-slice-height = <12>;
				qcom,mdss-dsc-slice-width = <620>;
				qcom,mdss-dsc-slice-per-pkt = <2>;
				qcom,mdss-dsc-bit-per-component = <10>;
				qcom,mdss-dsc-bit-per-pixel = <8>;
				qcom,mdss-dsc-block-prediction-enable;
			};
			timing@fhd_sdc_60{
				qcom,mdss-mdp-transfer-time-us = <7500>;
				qcom,mdss-mdp-transfer-time-us-min = <6000>;
				qcom,mdss-mdp-transfer-time-us-max = <7500>;
				qcom,mdss-dsi-panel-jitter = <0x4 0x1>;
				qcom,mdss-dsc-scr-version = <0x1>;
				qcom,mdss-dsc-version = <0x11>;
				qcom,mdss-dsi-panel-framerate = <60>;
				qcom,mdss-dsi-panel-clockrate = <1363200000>;
				qcom,mdss-dsi-panel-width = <1240>;
				qcom,mdss-dsi-panel-height = <2772>;

				qcom,mdss-dsi-h-front-porch = <64>;
				qcom,mdss-dsi-h-back-porch = <48>;
				qcom,mdss-dsi-h-pulse-width = <8>;
				qcom,mdss-dsi-v-back-porch = <8>;
				qcom,mdss-dsi-v-front-porch = <2>;
				qcom,mdss-dsi-v-pulse-width = <2>;
				qcom,mdss-dsi-h-sync-pulse = <0>;

				qcom,mdss-dsi-h-left-border = <0>;
				qcom,mdss-dsi-h-right-border = <0>;
				qcom,mdss-dsi-v-top-border = <0>;
				qcom,mdss-dsi-v-bottom-border = <0>;

				/* Apollo vsync config, need to measure TE signal */
				//oplus,apollo-panel-vsync-width = <13000>;
				//oplus,apollo-panel-vsync-period = <16600>;
				qcom,mdss-dsi-h-sync-skew = <0>;
				qcom,mdss-dsi-panel-vsync-source = <1>;
				qcom,mdss-dsi-qsync-min-fps-0 = <1314>;
				oplus,fod-on-vblank = <0>;
				oplus,fod-off-vblank = <0>;
				oplus,ofp-need-to-filter-backlight-dim-icon;
				qcom,mdss-dsi-bl-demura1-command = [
					/* 51hex > 0x644 */
					39 00 00 50 00 00 06 F0 55 AA 52 08 04
					39 00 00 50 00 00 02 6F 02
					39 00 00 50 00 00 03 EC 01 03
					39 00 00 50 00 00 02 6F A5
					39 00 00 10 00 00 07 EC 01 01 01 03 03 03
				];
				qcom,mdss-dsi-bl-demura2-command = [
					/* 0x644>51hex>=0x530 */
					39 00 00 50 00 00 06 F0 55 AA 52 08 04
					39 00 00 50 00 00 02 6F 02
					39 00 00 50 00 00 03 EC 03 0B
					39 00 00 50 00 00 02 6F A5
					39 00 00 10 00 00 07 EC 03 03 03 0B 0B 0B
				];
				qcom,mdss-dsi-bl-demura3-command = [
					/* 0x530>51hex>=0x33A */
					39 00 00 50 00 00 06 F0 55 AA 52 08 04
					39 00 00 50 00 00 02 6F 02
					39 00 00 50 00 00 03 EC 10 18
					39 00 00 50 00 00 02 6F A5
					39 00 00 10 00 00 07 EC 10 10 10 18 18 18
				];
				qcom,mdss-dsi-bl-demura4-command = [
					/* 0x339>51hex>=0x25C */
					39 00 00 50 00 00 06 F0 55 AA 52 08 04
					39 00 00 50 00 00 02 6F 02
					39 00 00 50 00 00 03 EC 15 1D
					39 00 00 50 00 00 02 6F A5
					39 00 00 10 00 00 07 EC 15 15 15 1D 1D 1D
				];
				qcom,mdss-dsi-bl-demura5-command = [
					/* 0x25C>51hex>=0x196 */
					39 00 00 50 00 00 06 F0 55 AA 52 08 04
					39 00 00 50 00 00 02 6F 02
					39 00 00 50 00 00 03 EC 15 2D
					39 00 00 50 00 00 02 6F A5
					39 00 00 10 00 00 07 EC 15 15 15 2D 2D 2D
				];
				qcom,mdss-dsi-bl-demura6-command = [
					/* 0x196>51hex>=0x008 */
					39 00 00 50 00 00 06 F0 55 AA 52 08 04
					39 00 00 50 00 00 02 6F 02
					39 00 00 50 00 00 03 EC 15 4D
					39 00 00 50 00 00 02 6F A5
					39 00 00 10 00 00 07 EC 15 15 15 4D 4D 4D
				];
				qcom,mdss-dsi-skipframe-dbv-command = [
					39 00 00 40 00 00 06 F0 55 AA 52 08 01
					39 00 00 40 00 00 02 6F 02
					39 00 00 40 00 00 11 E5 00 00 00 00 00 00 00 00 00 00 00 00 00 00 00 00
					39 00 00 40 00 00 02 6F 24
					39 00 00 40 00 00 0D E5 00 00 00 00 00 00 00 00 00 00 00 00
					39 00 00 40 00 00 02 6F 46
					39 00 00 40 00 00 0D E5 00 00 00 00 00 00 00 00 00 00 00 00
					39 00 00 40 00 00 02 6F 03
					39 00 00 40 00 00 19 C6 16 16 1F 23 23 23 23 23 23 23 23 21 23 23 23 23 23 23 18 18 21 23 23 23
					39 00 00 40 00 00 02 E5 B2
					39 00 00 40 00 00 02 6F 22
					39 00 00 40 00 00 02 E5 B2
					39 00 00 40 00 00 02 6F 44
					39 00 00 40 00 00 02 E5 B2
					39 00 00 40 00 00 06 F0 55 AA 52 08 05
					39 00 00 40 00 00 02 6F 12
					39 00 00 40 00 00 05 EC 00 00 00 00
					39 00 00 40 00 00 06 F0 55 AA 52 08 00
					39 00 00 40 00 00 02 6F 11
					39 00 00 40 00 00 04 B2 02 03 42
					39 00 00 00 00 00 03 51 03 FF
					];
				qcom,mdss-dsi-timing-switch-command = [
					/* switch60Hz */
					39 00 00 40 00 00 06 F0 55 AA 52 08 00
					39 00 00 00 11 00 02 2F 00
					39 00 00 40 00 00 02 6F A8
					39 00 00 40 00 00 03 BA 00 00
					39 00 00 40 00 00 02 6F B0
					39 00 00 40 00 00 05 BA 00 00 00 00
					39 00 00 40 00 00 02 2F 30
					39 00 00 40 00 00 02 6D 01
					39 00 00 00 00 00 05 35 00 00 00 01
					];
				qcom,mdss-dsi-on-command=[
					/*Skip frame*/
					39 00 00 40 00 00 06 F0 55 AA 52 08 00
					39 00 00 40 00 00 02 6F 1B
					39 00 00 40 00 00 02 BA 18
					39 00 00 40 00 00 02 6F 1C
					39 00 00 40 00 00 11 BA 01 01 01 01 00 01 02 03 00 01 02 03 00 00 00 00
					39 00 00 40 00 00 02 6F 2C
					39 00 00 40 00 00 11 BA 01 01 01 01 00 01 02 03 00 01 02 03 00 00 00 00
					39 00 00 40 00 00 02 6F 3C
					39 00 00 40 00 00 11 BA 01 01 01 01 00 01 02 03 00 01 02 03 00 00 00 00
					39 00 00 40 00 00 02 6F 4C
					39 00 00 40 00 00 11 BA 01 01 01 01 00 01 02 03 00 01 02 03 00 00 00 00
					39 00 00 40 00 00 02 6F 5C
					39 00 00 40 00 00 05 BA 01 01 01 01
					39 00 00 40 00 00 02 6F 6C
					39 00 00 40 00 00 05 BA 00 01 02 03
					39 00 00 40 00 00 02 6F 7C
					39 00 00 40 00 00 05 BA 00 01 02 03
					39 00 00 40 00 00 02 6F 8C
					39 00 00 40 00 00 05 BA 00 00 00 00
					39 00 00 40 00 00 02 6F 9C
					39 00 00 40 00 00 09 BA 11 11 11 11 11 11 11 11
					39 00 00 40 00 00 02 6F A4
					39 00 00 40 00 00 03 BA E4 E4
					39 00 00 40 00 00 02 6F A8
					39 00 00 40 00 00 04 BA 00 00 00
					39 00 00 40 00 00 02 6F B0
					39 00 00 40 00 00 05 BA 00 00 00 00
					39 00 00 40 00 00 02 6F 08
					39 00 00 40 00 00 17 BB 01 00 00 00 01 00 00 00 01 00 00 00 01 00 00 00 01 00 00 00 00 00
					39 00 00 40 00 00 06 F0 55 AA 52 08 01
					39 00 00 40 00 00 13 E5 B2 22 00 00 00 00 20 20 20 20 24 24 24 24 00 00 00 00
					39 00 00 40 00 00 02 6F 22
					39 00 00 40 00 00 13 E5 B2 22 00 00 00 00 20 20 20 20 24 24 24 24 00 00 00 00
					39 00 00 40 00 00 02 6F 44
					39 00 00 40 00 00 13 E5 B2 22 00 00 00 00 20 20 20 20 24 24 24 24 00 00 00 00
					39 00 00 40 00 00 02 6F 66
					39 00 00 40 00 00 13 E5 B2 22 00 00 00 00 20 20 20 20 24 24 24 24 00 00 00 00
					39 00 00 40 00 00 02 6F 0C
					39 00 00 40 00 00 03 CE 0D 11
					39 00 00 40 00 00 02 6F 27
					39 00 00 40 00 00 06 B9 AA AA AA 00 00
					39 00 00 40 00 00 02 6F 03
					39 00 00 40 00 00 07 C6 16 16 16 23 23 23
					39 00 00 40 00 00 02 6F 0C
					39 00 00 40 00 00 07 C6 16 16 16 23 23 23
					39 00 00 40 00 00 02 6F 15
					39 00 00 40 00 00 07 C6 16 16 16 23 23 23
					39 00 00 40 00 00 02 6F 1E
					39 00 00 40 00 00 07 C6 16 16 16 23 23 23
					39 00 00 40 00 00 06 F0 55 AA 52 08 00
					39 00 00 40 00 00 02 6F 13
					39 00 00 40 00 00 02 C2 D8
					39 00 00 40 00 00 06 F0 55 AA 52 08 05
					39 00 00 40 00 00 02 6F 12
					39 00 00 40 00 00 05 EC 00 00 00 00
					/* Optimize edge green */
					/*39 00 00 40 00 00 06 F0 55 AA 52 08 07*/
					/*39 00 00 40 00 00 0E B4 C0 80 80 80 80 50 80 80 80 80 80 50 80*/
					/* Vsync Hsync output */
					39 00 00 40 00 00 06 F0 55 AA 52 08 00
					39 00 00 40 00 00 02 6F 02
					39 00 00 00 00 00 03 BE 49 4C
					/* AVDD=7.9 */
					/* 39 00 00 40 00 00 06 F0 55 AA 52 08 00 */
					/* 39 00 00 40 00 00 02 6F 07 */
					/* 39 00 00 40 00 00 02 B5 4E */
					/* HBM L0 glows green */
					39 00 00 40 00 00 02 B5 80
					39 00 00 40 00 00 02 6F 2C
					39 00 00 00 00 00 02 B5 03
					39 00 00 40 00 00 05 FF AA 55 A5 81
					39 00 00 40 00 00 02 6F 19
					39 00 00 40 00 00 02 FB 00
					39 00 00 40 00 00 02 6F 05
					39 00 00 40 00 00 02 FE 34
					39 00 00 40 00 00 05 FF AA 55 A5 80
					39 00 00 40 00 00 02 6F 1A
					39 00 00 40 00 00 02 F4 55
					39 00 00 40 00 00 05 FF AA 55 A5 83
					39 00 00 40 00 00 02 6F 12
					39 00 00 40 00 00 02 FE 41
					39 00 00 40 00 00 02 5F 00
					39 00 00 40 00 00 02 26 00
					39 00 00 40 00 00 02 26 00
					39 00 00 40 00 00 02 17 10
					39 00 00 40 00 00 05 2A 00 00 04 D7
					39 00 00 00 00 00 05 2B 00 00 0A D3
					/* Fre 120Hz */
					39 00 00 00 00 00 02 2F 00
					/* TE ON */
					/*39 00 00 40 00 00 02 35 00*/
					39 00 00 00 00 00 03 44 00 00
					/* Nor 51 */
					39 00 00 40 00 00 03 51 00 00
					39 00 00 00 00 00 02 6F 04
					/* AOD 51 */
					39 00 00 40 00 00 03 51 00 00
					39 00 00 40 00 00 02 53 20
					39 00 00 00 00 00 03 90 03 03
					/* 10bit DSC */
					39 00 00 40 00 00 13 91 AB 28 00 0C F2 00 02 85 01 0F 00 08 0A E9 07 5F 10 F0
					39 00 00 40 00 00 05 FF AA 55 A5 81
					39 00 00 40 00 00 02 6F 24
					39 00 00 40 00 00 15 FB 00 03 04 55 77 77 77 99 9D 00 00 06 88 9A BB BC DE EF F0 11
					39 00 00 40 00 00 05 FF AA 55 A5 81
					39 00 00 40 00 00 02 6F 0E
					39 00 00 40 00 00 02 F5 00
					39 00 00 40 00 00 05 FF AA 55 A5 80
					39 00 00 40 00 00 02 6F 0F
					39 00 00 40 00 00 02 FC 00
					39 00 00 40 00 00 02 6F 09
					39 00 00 40 00 00 03 FC FC F0
					39 00 00 40 00 00 05 FF AA 55 A5 80
					39 00 00 40 00 00 02 6F 0A
					39 00 00 40 00 00 04 F6 70 70 70
					39 00 00 40 00 00 02 6F 0E
					39 00 00 00 00 00 02 F6 60
					/* OSC start */
					39 00 00 40 00 00 05 FF AA 55 A5 80
					39 00 00 40 00 00 02 6F 11
					/* OSC2 145Mhz */
					39 00 00 40 00 00 03 F8 01 8E
					39 00 00 40 00 00 02 6F 2D
					/* OSC1 121.9Mhz */
					39 00 00 40 00 00 03 F8 00 FC
					39 00 00 40 00 00 02 6F 01
					39 00 00 40 00 00 02 1F 06
					39 00 00 40 00 00 05 FF AA 55 A5 81
					39 00 00 40 00 00 02 6F 1E
					39 00 00 00 00 00 02 FB 0F
					/* OSC end */
					39 00 00 40 00 00 05 FF AA 55 A5 83
					39 00 00 40 00 00 02 6F 12
					39 00 00 40 00 00 02 FE 41
					39 00 00 40 00 00 05 FF AA 55 A5 80
					39 00 00 40 00 00 02 6F 19
					39 00 00 40 00 00 02 F2 00
					39 00 00 40 00 00 05 FF AA 55 A5 81
					39 00 00 40 00 00 02 6F 02
					39 00 00 40 00 00 02 F9 04
					39 00 00 40 00 00 02 5A 00
					/* AOD remove black frame */
					39 00 00 00 00 00 06 F0 55 AA 52 08 01
					39 00 00 00 00 00 06 D2 00 00 00 00 15
					15 00 00 00 00 00 02 6F 05
					39 00 00 00 00 00 04 D2 01 00 00
					15 00 00 00 00 00 02 6F 0E
					39 00 00 00 00 00 06 D2 02 00 10 05 88
					39 00 00 00 00 00 0B E4 80 00 00 00 00 00 00 00 00 33
					15 00 00 00 00 00 02 6F 0A
					39 00 00 00 00 00 07 E4 80 00 00 10 00 53
					/* AOD off splash */
					39 00 00 40 00 00 06 F0 55 AA 52 08 01
					39 00 00 40 00 00 02 6F 0E
					39 00 00 00 00 00 06 D2 02 00 10 05 82
					/* 11H sleep out */
					39 00 00 00 80 00 02 11 00
					/* timing-switch */
					39 00 00 40 00 00 06 F0 55 AA 52 08 00
					39 00 00 00 11 00 02 2F 00
					39 00 00 40 00 00 02 6F A8
					39 00 00 40 00 00 03 BA 00 00
					39 00 00 40 00 00 02 6F B0
					39 00 00 40 00 00 05 BA 00 00 00 00
					39 00 00 40 00 00 02 2F 30
					39 00 00 40 00 00 02 6D 01
					39 00 00 00 00 00 05 35 00 00 00 01
					05 00 00 00 00 00 01 29
					/* OSC Tracking for 60/90/120 fps */
					39 00 00 40 00 00 06 F0 55 AA 52 08 01
					39 00 00 00 11 00 2A C3 DD 06 22 15 F9 00 06 20 15 FF 00 03 E7 16 06 2B 1D 03 E7 16 06 2B 1D 03 E7 16 06 2B 1D 03 E7 16 06 2B 1D 03 E7 16 06 2B 1D
				];

				qcom,mdss-dsi-panel-info-switch-page-command = [
					/*read panel info switch page 01*/
					39 00 00 00 00 00 06 F0 55 AA 52 08 01
				];
				qcom,mdss-dsi-default-switch-page-command = [
					/*switch default page*/
					39 00 00 00 00 00 06 F0 55 AA 52 08 00
				];

				qcom,mdss-dsi-qsync-min-fps-0-command = [
					/* SDC Auto Off */
					15 00 00 40 00 00 02 2F 00
					15 00 00 40 00 00 02 2F 30
					15 00 00 00 00 00 02 6D 00
				];

				qcom,mdss-dsi-post-on-backlight = [
					/* Display On */
					05 00 00 00 00 00 01 29
				];
				qcom,mdss-dsi-off-command=[
					05 00 00 00 0A 00 01 28
					05 00 00 00 78 00 01 10
				];
				qcom,mdss-dsi-lp1-command = [
					/* FD OFF */
					39 00 00 00 00 00 06 F0 55 AA 52 08 00
					15 00 00 00 00 00 02 6F 0C
					39 00 00 00 00 00 03 B5 50 4B
					39 00 00 00 00 00 05 35 00 00 00 00
					39 00 00 00 00 00 03 44 00 00
					/* AOD Mode 30Hz */
					15 00 00 00 00 00 02 2F 00
					05 00 00 00 00 00 01 39
					15 00 00 00 00 00 02 65 01
					/* 50nit */
					15 00 00 00 00 00 02 6F 04
					39 00 00 00 00 00 03 51 02 FF
				];
				qcom,mdss-dsi-nolp-command = [
					/* AOD OFF */
					39 00 00 00 00 00 06 F0 55 AA 52 08 00
					15 00 00 00 00 00 02 6F 0C
					39 00 00 00 00 00 03 B5 4F 4B
					15 00 00 00 00 00 02 65 00
					05 00 00 00 00 00 01 38
					/* Switch to 60Hz */
					15 00 00 00 00 00 02 2F 30
					15 00 00 00 00 00 02 6D 01
					39 00 00 00 00 00 05 35 00 00 00 01
					39 00 00 00 00 00 03 44 00 00
					39 00 00 00 28 00 03 51 00 00
				];
				qcom,mdss-dsi-hbm-off-command = [
					//39 00 00 00 00 00 03 51 0D BB
				];
				qcom,mdss-dsi-hbm-on-command = [
					39 00 00 40 00 00 06 F0 55 AA 52 08 04
					39 00 00 40 00 00 02 6F 02
					39 00 00 40 00 00 03 EC 01 03
					39 00 00 40 00 00 02 6F A5
					39 00 00 00 00 00 07 EC 01 01 01 03 03 03
					39 00 00 40 00 00 06 F0 55 AA 52 08 01
					39 00 00 40 00 00 02 6F 02
					39 00 00 40 00 00 09 E5 00 00 00 00 20 20 20 00
					39 00 00 40 00 00 02 6F 46
					39 00 00 40 00 00 0D E5 00 00 00 00 20 20 20 00 28 28 28 00
					39 00 00 40 00 00 02 6F 03
					39 00 00 40 00 00 19 C6 37 37 37 23 23 23 23 23 23 23 23 23 23 23 23 23 23 23 37 37 37 23 23 23
					39 00 00 40 00 00 02 E5 B2
					39 00 00 40 00 00 02 6F 44
					39 00 00 40 00 00 02 E5 B2
					39 00 00 40 00 00 06 F0 55 AA 52 08 05
					39 00 00 40 00 00 02 6F 12
					39 00 00 40 00 00 05 EC 00 00 00 00
					39 00 00 40 00 00 06 F0 55 AA 52 08 00
					39 00 00 40 00 00 02 6F 11
					39 00 00 40 00 00 04 B2 02 03 42
					39 00 00 00 00 00 03 51 0F 00
				];
				qcom,mdss-dsi-aod-high-mode-command = [
					/* AOD 50nit */
					15 00 00 40 00 00 02 6F 04
					39 00 00 00 00 00 03 51 02 FF
				];
				qcom,mdss-dsi-aod-low-mode-command = [
					/* AOD 10nit */
					15 00 00 40 00 00 02 6F 04
					39 00 00 00 00 00 03 51 01 FF
				];
				qcom,mdss-dsi-timing-switch-command-state = "dsi_hs_mode";
				qcom,mdss-dsi-on-command-state = "dsi_lp_mode";
				qcom,mdss-dsi-off-command-state = "dsi_hs_mode";
				qcom,mdss-dsi-hbm-on-command-state = "dsi_lp_mode";
				qcom,mdss-dsi-hbm-off-command-state = "dsi_lp_mode";
				qcom,mdss-dsi-skipframe-dbv-command-state = "dsi_hs_mode";
				qcom,mdss-dsi-qsync-min-fps-0-command-state = "dsi_hs_mode";
				qcom,mdss-dsi-bl-demura1-command-state = "dsi_hs_mode";
				qcom,mdss-dsi-bl-demura2-command-state = "dsi_hs_mode";
				qcom,mdss-dsi-bl-demura3-command-state = "dsi_hs_mode";
				qcom,mdss-dsi-bl-demura4-command-state = "dsi_hs_mode";
				qcom,mdss-dsi-bl-demura5-command-state = "dsi_hs_mode";
				qcom,mdss-dsi-bl-demura6-command-state = "dsi_hs_mode";
				qcom,mdss-dsi-panel-info-switch-page-command-state = "dsi_lp_mode";
				qcom,mdss-dsi-default-switch-page-command-state = "dsi_lp_mode";

				qcom,lm-split = <620 620>;
				qcom,compression-mode = "dsc";
				qcom,mdss-dsc-encoders = <2>;
				qcom,mdss-dsc-slice-height = <12>;
				qcom,mdss-dsc-slice-width = <620>;
				qcom,mdss-dsc-slice-per-pkt = <2>;
				qcom,mdss-dsc-bit-per-component = <10>;
				qcom,mdss-dsc-bit-per-pixel = <8>;
				qcom,mdss-dsc-block-prediction-enable;
			};
			timing@fhd_sdc_144{
				qcom,mdss-mdp-transfer-time-us = <6000>;
				qcom,mdss-mdp-transfer-time-us-min = <6000>;
				qcom,mdss-mdp-transfer-time-us-max = <6000>;
				qcom,mdss-dsi-panel-jitter = <0x4 0x1>;
				qcom,mdss-dsc-scr-version = <0x1>;
				qcom,mdss-dsc-version = <0x11>;
				qcom,mdss-dsi-panel-framerate = <144>;
				qcom,mdss-dsi-panel-clockrate = <1363200000>;
				qcom,mdss-dsi-panel-width = <1240>;
				qcom,mdss-dsi-panel-height = <2772>;

				qcom,mdss-dsi-h-front-porch = <64>;
				qcom,mdss-dsi-h-back-porch = <48>;
				qcom,mdss-dsi-h-pulse-width = <8>;
				qcom,mdss-dsi-v-back-porch = <8>;
				qcom,mdss-dsi-v-front-porch = <2>;
				qcom,mdss-dsi-v-pulse-width = <2>;
				qcom,mdss-dsi-h-sync-pulse = <0>;

				qcom,mdss-dsi-h-left-border = <0>;
				qcom,mdss-dsi-h-right-border = <0>;
				qcom,mdss-dsi-v-top-border = <0>;
				qcom,mdss-dsi-v-bottom-border = <0>;

				/* Apollo vsync config, need to measure TE signal */
				//oplus,apollo-panel-vsync-width = <13000>;
				//oplus,apollo-panel-vsync-period = <16600>;
				qcom,mdss-dsi-h-sync-skew = <0>;
				qcom,mdss-dsi-panel-vsync-source = <1>;
				qcom,mdss-dsi-qsync-min-fps-0 = <1314>;
				oplus,fod-on-vblank = <0>;
				oplus,fod-off-vblank = <0>;
				oplus,ofp-need-to-filter-backlight-dim-icon;
				qcom,mdss-dsi-bl-demura1-command = [
					/* 51hex > 0x644 */
					39 00 00 50 00 00 06 F0 55 AA 52 08 04
					39 00 00 50 00 00 02 6F 02
					39 00 00 50 00 00 03 EC 01 03
					39 00 00 50 00 00 02 6F A5
					39 00 00 10 00 00 07 EC 01 01 01 03 03 03
				];
				qcom,mdss-dsi-bl-demura2-command = [
					/* 0x644>51hex>=0x530 */
					39 00 00 50 00 00 06 F0 55 AA 52 08 04
					39 00 00 50 00 00 02 6F 02
					39 00 00 50 00 00 03 EC 03 0B
					39 00 00 50 00 00 02 6F A5
					39 00 00 10 00 00 07 EC 03 03 03 0B 0B 0B
				];
				qcom,mdss-dsi-bl-demura3-command = [
					/* 0x530>51hex>=0x33A */
					39 00 00 50 00 00 06 F0 55 AA 52 08 04
					39 00 00 50 00 00 02 6F 02
					39 00 00 50 00 00 03 EC 10 18
					39 00 00 50 00 00 02 6F A5
					39 00 00 10 00 00 07 EC 10 10 10 18 18 18
				];
				qcom,mdss-dsi-bl-demura4-command = [
					/* 0x339>51hex>=0x25C */
					39 00 00 50 00 00 06 F0 55 AA 52 08 04
					39 00 00 50 00 00 02 6F 02
					39 00 00 50 00 00 03 EC 15 1D
					39 00 00 50 00 00 02 6F A5
					39 00 00 10 00 00 07 EC 15 15 15 1D 1D 1D
				];
				qcom,mdss-dsi-bl-demura5-command = [
					/* 0x25C>51hex>=0x196 */
					39 00 00 50 00 00 06 F0 55 AA 52 08 04
					39 00 00 50 00 00 02 6F 02
					39 00 00 50 00 00 03 EC 15 2D
					39 00 00 50 00 00 02 6F A5
					39 00 00 10 00 00 07 EC 15 15 15 2D 2D 2D
				];
				qcom,mdss-dsi-bl-demura6-command = [
					/* 0x196>51hex>=0x008 */
					39 00 00 50 00 00 06 F0 55 AA 52 08 04
					39 00 00 50 00 00 02 6F 02
					39 00 00 50 00 00 03 EC 15 4D
					39 00 00 50 00 00 02 6F A5
					39 00 00 10 00 00 07 EC 15 15 15 4D 4D 4D
				];
				qcom,mdss-dsi-skipframe-dbv-command = [
					39 00 00 40 00 00 06 F0 55 AA 52 08 01
					39 00 00 40 00 00 02 6F 02
					39 00 00 40 00 00 11 E5 00 00 00 00 00 00 00 00 00 00 00 00 00 00 00 00
					39 00 00 40 00 00 02 6F 24
					39 00 00 40 00 00 0D E5 00 00 00 00 00 00 00 00 00 00 00 00
					39 00 00 40 00 00 02 6F 46
					39 00 00 40 00 00 0D E5 00 00 00 00 00 00 00 00 00 00 00 00
					39 00 00 40 00 00 02 6F 03
					39 00 00 40 00 00 19 C6 16 16 1F 23 23 23 23 23 23 23 23 21 23 23 23 23 23 23 18 18 21 23 23 23
					39 00 00 40 00 00 02 E5 B2
					39 00 00 40 00 00 02 6F 22
					39 00 00 40 00 00 02 E5 B2
					39 00 00 40 00 00 02 6F 44
					39 00 00 40 00 00 02 E5 B2
					39 00 00 40 00 00 06 F0 55 AA 52 08 05
					39 00 00 40 00 00 02 6F 12
					39 00 00 40 00 00 05 EC 00 00 00 00
					39 00 00 40 00 00 06 F0 55 AA 52 08 00
					39 00 00 40 00 00 02 6F 11
					39 00 00 40 00 00 04 B2 02 03 42
					39 00 00 00 00 00 03 51 03 FF
					];
				qcom,mdss-dsi-timing-switch-command = [
					/* switch */
					39 00 00 40 00 00 06 F0 55 AA 52 08 00
					39 00 00 00 0A 00 02 2F 02
					39 00 00 40 00 00 02 BE 47
					39 00 00 40 00 00 02 6F A8
					39 00 00 40 00 00 03 BA 22 22
					39 00 00 40 00 00 02 6F B0
					39 00 00 40 00 00 05 BA 22 22 00 00
					39 00 00 40 00 00 02 2F 30
					39 00 00 40 00 00 02 6D 00
					39 00 00 00 00 00 05 35 00 00 00 00
					];
				qcom,mdss-dsi-on-command=[
					/*Skip frame*/
					39 00 00 40 00 00 06 F0 55 AA 52 08 00
					39 00 00 40 00 00 02 6F 1B
					39 00 00 40 00 00 02 BA 18
					39 00 00 40 00 00 02 6F 1C
					39 00 00 40 00 00 11 BA 01 01 01 01 00 01 02 03 00 01 02 03 00 00 00 00
					39 00 00 40 00 00 02 6F 2C
					39 00 00 40 00 00 11 BA 01 01 01 01 00 01 02 03 00 01 02 03 00 00 00 00
					39 00 00 40 00 00 02 6F 3C
					39 00 00 40 00 00 11 BA 01 01 01 01 00 01 02 03 00 01 02 03 00 00 00 00
					39 00 00 40 00 00 02 6F 4C
					39 00 00 40 00 00 11 BA 01 01 01 01 00 01 02 03 00 01 02 03 00 00 00 00
					39 00 00 40 00 00 02 6F 5C
					39 00 00 40 00 00 05 BA 01 01 01 01
					39 00 00 40 00 00 02 6F 6C
					39 00 00 40 00 00 05 BA 00 01 02 03
					39 00 00 40 00 00 02 6F 7C
					39 00 00 40 00 00 05 BA 00 01 02 03
					39 00 00 40 00 00 02 6F 8C
					39 00 00 40 00 00 05 BA 00 00 00 00
					39 00 00 40 00 00 02 6F 9C
					39 00 00 40 00 00 09 BA 11 11 11 11 11 11 11 11
					39 00 00 40 00 00 02 6F A4
					39 00 00 40 00 00 03 BA E4 E4
					39 00 00 40 00 00 02 6F A8
					39 00 00 40 00 00 04 BA 00 00 00
					39 00 00 40 00 00 02 6F B0
					39 00 00 40 00 00 05 BA 00 00 00 00
					39 00 00 40 00 00 02 6F 08
					39 00 00 40 00 00 17 BB 01 00 00 00 01 00 00 00 01 00 00 00 01 00 00 00 01 00 00 00 00 00
					39 00 00 40 00 00 06 F0 55 AA 52 08 01
					39 00 00 40 00 00 13 E5 B2 22 00 00 00 00 20 20 20 20 24 24 24 24 00 00 00 00
					39 00 00 40 00 00 02 6F 22
					39 00 00 40 00 00 13 E5 B2 22 00 00 00 00 20 20 20 20 24 24 24 24 00 00 00 00
					39 00 00 40 00 00 02 6F 44
					39 00 00 40 00 00 13 E5 B2 22 00 00 00 00 20 20 20 20 24 24 24 24 00 00 00 00
					39 00 00 40 00 00 02 6F 66
					39 00 00 40 00 00 13 E5 B2 22 00 00 00 00 20 20 20 20 24 24 24 24 00 00 00 00
					39 00 00 40 00 00 02 6F 0C
					39 00 00 40 00 00 03 CE 0D 11
					39 00 00 40 00 00 02 6F 27
					39 00 00 40 00 00 06 B9 AA AA AA 00 00
					39 00 00 40 00 00 02 6F 03
					39 00 00 40 00 00 07 C6 16 16 16 23 23 23
					39 00 00 40 00 00 02 6F 0C
					39 00 00 40 00 00 07 C6 16 16 16 23 23 23
					39 00 00 40 00 00 02 6F 15
					39 00 00 40 00 00 07 C6 16 16 16 23 23 23
					39 00 00 40 00 00 02 6F 1E
					39 00 00 40 00 00 07 C6 16 16 16 23 23 23
					39 00 00 40 00 00 06 F0 55 AA 52 08 00
					39 00 00 40 00 00 02 6F 13
					39 00 00 40 00 00 02 C2 D8
					39 00 00 40 00 00 06 F0 55 AA 52 08 05
					39 00 00 40 00 00 02 6F 12
					39 00 00 40 00 00 05 EC 00 00 00 00
					/* Optimize edge green */
					/*39 00 00 40 00 00 06 F0 55 AA 52 08 07*/
					/*39 00 00 40 00 00 0E B4 C0 80 80 80 80 50 80 80 80 80 80 50 80*/
					/* Vsync Hsync output */
					39 00 00 40 00 00 06 F0 55 AA 52 08 00
					39 00 00 40 00 00 02 6F 02
					39 00 00 00 00 00 03 BE 49 4C
					/* AVDD=7.9 */
					/* 39 00 00 40 00 00 06 F0 55 AA 52 08 00 */
					/* 39 00 00 40 00 00 02 6F 07 */
					/* 39 00 00 40 00 00 02 B5 4E */
					/* HBM L0 glows green */
					39 00 00 40 00 00 02 B5 80
					39 00 00 40 00 00 02 6F 2C
					39 00 00 00 00 00 02 B5 03
					39 00 00 40 00 00 05 FF AA 55 A5 81
					39 00 00 40 00 00 02 6F 19
					39 00 00 40 00 00 02 FB 00
					39 00 00 40 00 00 02 6F 05
					39 00 00 40 00 00 02 FE 34
					39 00 00 40 00 00 05 FF AA 55 A5 80
					39 00 00 40 00 00 02 6F 1A
					39 00 00 40 00 00 02 F4 55
					39 00 00 40 00 00 05 FF AA 55 A5 83
					39 00 00 40 00 00 02 6F 12
					39 00 00 40 00 00 02 FE 41
					39 00 00 40 00 00 02 5F 00
					39 00 00 40 00 00 02 26 00
					39 00 00 40 00 00 02 26 00
					39 00 00 40 00 00 02 17 10
					39 00 00 40 00 00 05 2A 00 00 04 D7
					39 00 00 00 00 00 05 2B 00 00 0A D3
					/* Fre 144Hz */
					39 00 00 00 00 00 02 2F 02
					/* TE ON */
					39 00 00 40 00 00 02 35 00
					39 00 00 00 00 00 03 44 00 00
					/* Nor 51 */
					39 00 00 40 00 00 03 51 00 00
					39 00 00 00 00 00 02 6F 04
					/* AOD 51 */
					39 00 00 40 00 00 03 51 00 00
					39 00 00 40 00 00 02 53 20
					39 00 00 00 00 00 03 90 03 03
					/* 10bit DSC */
					39 00 00 40 00 00 13 91 AB 28 00 0C F2 00 02 85 01 0F 00 08 0A E9 07 5F 10 F0
					39 00 00 40 00 00 05 FF AA 55 A5 81
					39 00 00 40 00 00 02 6F 24
					39 00 00 40 00 00 15 FB 00 03 04 55 77 77 77 99 9D 00 00 06 88 9A BB BC DE EF F0 11
					39 00 00 40 00 00 05 FF AA 55 A5 81
					39 00 00 40 00 00 02 6F 0E
					39 00 00 40 00 00 02 F5 00
					39 00 00 40 00 00 05 FF AA 55 A5 80
					39 00 00 40 00 00 02 6F 0F
					39 00 00 40 00 00 02 FC 00
					39 00 00 40 00 00 02 6F 09
					39 00 00 40 00 00 03 FC FC F0
					39 00 00 40 00 00 05 FF AA 55 A5 80
					39 00 00 40 00 00 02 6F 0A
					39 00 00 40 00 00 04 F6 70 70 70
					39 00 00 40 00 00 02 6F 0E
					39 00 00 00 00 00 02 F6 60
					/* OSC start */
					39 00 00 40 00 00 05 FF AA 55 A5 80
					39 00 00 40 00 00 02 6F 11
					/* OSC2 145Mhz */
					39 00 00 40 00 00 03 F8 01 8E
					39 00 00 40 00 00 02 6F 2D
					/* OSC1 121.9Mhz */
					39 00 00 40 00 00 03 F8 00 FC
					39 00 00 40 00 00 02 6F 01
					39 00 00 40 00 00 02 1F 06
					39 00 00 40 00 00 05 FF AA 55 A5 81
					39 00 00 40 00 00 02 6F 1E
					39 00 00 00 00 00 02 FB 0F
					/* OSC end */
					39 00 00 40 00 00 05 FF AA 55 A5 83
					39 00 00 40 00 00 02 6F 12
					39 00 00 40 00 00 02 FE 41
					39 00 00 40 00 00 05 FF AA 55 A5 80
					39 00 00 40 00 00 02 6F 19
					39 00 00 40 00 00 02 F2 00
					39 00 00 40 00 00 05 FF AA 55 A5 81
					39 00 00 40 00 00 02 6F 02
					39 00 00 40 00 00 02 F9 04
					39 00 00 40 00 00 02 5A 00
					/* AOD remove black frame */
					39 00 00 00 00 00 06 F0 55 AA 52 08 01
					39 00 00 00 00 00 06 D2 00 00 00 00 15
					15 00 00 00 00 00 02 6F 05
					39 00 00 00 00 00 04 D2 01 00 00
					15 00 00 00 00 00 02 6F 0E
					39 00 00 00 00 00 06 D2 02 00 10 05 88
					39 00 00 00 00 00 0B E4 80 00 00 00 00 00 00 00 00 33
					15 00 00 00 00 00 02 6F 0A
					39 00 00 00 00 00 07 E4 80 00 00 10 00 53
					/* AOD off splash */
					39 00 00 40 00 00 06 F0 55 AA 52 08 01
					39 00 00 40 00 00 02 6F 0E
					39 00 00 00 00 00 06 D2 02 00 10 05 82
					/* 11H sleep out */
					39 00 00 00 80 00 02 11 00
					39 00 00 40 00 00 06 F0 55 AA 52 08 00
					39 00 00 00 0A 00 02 2F 02
					39 00 00 40 00 00 02 BE 47
					39 00 00 40 00 00 02 6F A8
					39 00 00 40 00 00 03 BA 22 22
					39 00 00 40 00 00 02 6F B0
					39 00 00 40 00 00 05 BA 22 22 00 00
					39 00 00 40 00 00 02 2F 30
					39 00 00 40 00 00 02 6D 00
					39 00 00 00 00 00 05 35 00 00 00 00
					05 00 00 00 00 00 01 29
					/* OSC Tracking for 60/90/120 fps */
					39 00 00 40 00 00 06 F0 55 AA 52 08 01
					39 00 00 00 11 00 2A C3 DD 06 22 15 F9 00 06 20 15 FF 00 03 E7 16 06 2B 1D 03 E7 16 06 2B 1D 03 E7 16 06 2B 1D 03 E7 16 06 2B 1D 03 E7 16 06 2B 1D
				];

				qcom,mdss-dsi-panel-info-switch-page-command = [
					/*read panel info switch page 01*/
					39 00 00 00 00 00 06 F0 55 AA 52 08 01
				];
				qcom,mdss-dsi-default-switch-page-command = [
					/*switch default page*/
					39 00 00 00 00 00 06 F0 55 AA 52 08 00
				];

				qcom,mdss-dsi-qsync-on-commands = [
					/* SDC Auto On */
				];
				qcom,mdss-dsi-qsync-off-commands = [
					/* SDC Auto Off */
				];
				qcom,mdss-dsi-qsync-min-fps-0-command = [
					/* SDC Auto Off */
					15 00 00 40 00 00 02 2F 02
					15 00 00 40 00 00 02 2F 30
					15 00 00 00 00 00 02 6D 00
				];
				qcom,mdss-dsi-qsync-min-fps-1-command = [
					/* SDC Auto On */
				];

				qcom,mdss-dsi-post-on-backlight = [
					/* Display On */
					05 00 00 00 00 00 01 29
				];
				qcom,mdss-dsi-off-command=[
					05 00 00 00 0A 00 01 28
					05 00 00 00 78 00 01 10
				];
				qcom,mdss-dsi-lp1-command = [
					/* AOD Mode ON Setting */
					39 00 00 00 00 00 06 F0 55 AA 52 08 00
					15 00 00 00 00 00 02 6F 0C
					39 00 00 00 00 00 03 B5 50 4B
					39 00 00 00 00 00 05 35 00 00 00 00
					39 00 00 00 00 00 03 44 00 00
					15 00 00 00 00 00 02 2F 00
					05 00 00 00 00 00 01 39
					15 00 00 00 00 00 02 65 01
					15 00 00 00 00 00 02 6F 04
					39 00 00 00 00 00 03 51 02 FF
				];
				qcom,mdss-dsi-nolp-command = [
					/* AOD OFF */
					39 00 00 00 00 00 06 F0 55 AA 52 08 00
					15 00 00 00 00 00 02 6F 0C
					39 00 00 00 00 00 03 B5 4F 4B
					15 00 00 00 00 00 02 65 00
					05 00 00 00 00 00 01 38
					15 00 00 00 00 00 02 2F 30
					15 00 00 00 00 00 02 6D 00
					39 00 00 00 00 00 05 35 00 00 00 00
					39 00 00 00 00 00 03 44 00 00
					39 00 00 00 28 00 03 51 00 00
				];
				qcom,mdss-dsi-hbm-off-command = [
					//39 00 00 00 00 00 03 51 0D BB
				];
				qcom,mdss-dsi-hbm-on-command = [
					39 00 00 40 00 00 06 F0 55 AA 52 08 04
					39 00 00 40 00 00 02 6F 02
					39 00 00 40 00 00 03 EC 01 03
					39 00 00 40 00 00 02 6F A5
					39 00 00 00 00 00 07 EC 01 01 01 03 03 03
					39 00 00 40 00 00 06 F0 55 AA 52 08 01
					39 00 00 40 00 00 02 6F 02
					39 00 00 40 00 00 09 E5 00 00 00 00 20 20 20 00
					39 00 00 40 00 00 02 6F 46
					39 00 00 40 00 00 0D E5 00 00 00 00 20 20 20 00 28 28 28 00
					39 00 00 40 00 00 02 6F 03
					39 00 00 40 00 00 19 C6 37 37 37 23 23 23 23 23 23 23 23 23 23 23 23 23 23 23 37 37 37 23 23 23
					39 00 00 40 00 00 02 E5 B2
					39 00 00 40 00 00 02 6F 44
					39 00 00 40 00 00 02 E5 B2
					39 00 00 40 00 00 06 F0 55 AA 52 08 05
					39 00 00 40 00 00 02 6F 12
					39 00 00 40 00 00 05 EC 00 00 00 00
					39 00 00 40 00 00 06 F0 55 AA 52 08 00
					39 00 00 40 00 00 02 6F 11
					39 00 00 40 00 00 04 B2 02 03 42
					39 00 00 00 00 00 03 51 0F 00
				];
				qcom,mdss-dsi-aod-high-mode-command = [
					/* AOD 50nit */
					15 00 00 40 00 00 02 6F 04
					39 00 00 00 00 00 03 51 02 FF
				];
				qcom,mdss-dsi-aod-low-mode-command = [
					/* AOD 10nit */
					15 00 00 40 00 00 02 6F 04
					39 00 00 00 00 00 03 51 01 FF
				];
				qcom,mdss-dsi-timing-switch-command-state = "dsi_hs_mode";
				qcom,mdss-dsi-on-command-state = "dsi_lp_mode";
				qcom,mdss-dsi-off-command-state = "dsi_hs_mode";
				qcom,mdss-dsi-hbm-on-command-state = "dsi_lp_mode";
				qcom,mdss-dsi-hbm-off-command-state = "dsi_lp_mode";
				qcom,mdss-dsi-skipframe-dbv-command-state = "dsi_hs_mode";
				qcom,mdss-dsi-qsync-min-fps-0-command-state = "dsi_hs_mode";
				qcom,mdss-dsi-bl-demura1-command-state = "dsi_hs_mode";
				qcom,mdss-dsi-bl-demura2-command-state = "dsi_hs_mode";
				qcom,mdss-dsi-bl-demura3-command-state = "dsi_hs_mode";
				qcom,mdss-dsi-bl-demura4-command-state = "dsi_hs_mode";
				qcom,mdss-dsi-bl-demura5-command-state = "dsi_hs_mode";
				qcom,mdss-dsi-bl-demura6-command-state = "dsi_hs_mode";
				qcom,mdss-dsi-panel-info-switch-page-command-state = "dsi_lp_mode";
				qcom,mdss-dsi-default-switch-page-command-state = "dsi_lp_mode";

				qcom,lm-split = <620 620>;
				qcom,compression-mode = "dsc";
				qcom,mdss-dsc-encoders = <2>;
				qcom,mdss-dsc-slice-height = <12>;
				qcom,mdss-dsc-slice-width = <620>;
				qcom,mdss-dsc-slice-per-pkt = <2>;
				qcom,mdss-dsc-bit-per-component = <10>;
				qcom,mdss-dsc-bit-per-pixel = <8>;
				qcom,mdss-dsc-block-prediction-enable;
			};
			timing@fhd_oplus_120{
				qcom,mdss-mdp-transfer-time-us = <7500>;
				qcom,mdss-mdp-transfer-time-us-min = <6000>;
				qcom,mdss-mdp-transfer-time-us-max = <7500>;
				qcom,mdss-dsi-panel-jitter = <0x4 0x1>;
				qcom,mdss-dsc-scr-version = <0x1>;
				qcom,mdss-dsc-version = <0x11>;
				qcom,mdss-dsi-panel-framerate = <120>;
				qcom,mdss-dsi-panel-clockrate = <1363200000>;
				qcom,mdss-dsi-panel-width = <1240>;
				qcom,mdss-dsi-panel-height = <2772>;

				qcom,mdss-dsi-h-front-porch = <4>;
				qcom,mdss-dsi-h-back-porch = <4>;
				qcom,mdss-dsi-h-pulse-width = <4>;
				qcom,mdss-dsi-v-back-porch = <2>;
				qcom,mdss-dsi-v-front-porch = <2>;
				qcom,mdss-dsi-v-pulse-width = <2>;
				qcom,mdss-dsi-h-sync-pulse = <0>;

				qcom,mdss-dsi-h-left-border = <0>;
				qcom,mdss-dsi-h-right-border = <0>;
				qcom,mdss-dsi-v-top-border = <0>;
				qcom,mdss-dsi-v-bottom-border = <0>;

				/* Apollo vsync config, need to measure TE signal */
				//oplus,apollo-panel-vsync-width = <13000>;
				//oplus,apollo-panel-vsync-period = <16600>;

				/*oplus adfr*/
				qcom,mdss-dsi-h-sync-skew = <2>;
				qcom,mdss-dsi-qsync-min-fps-0 = <30>;
				qcom,mdss-dsi-qsync-min-fps-1 = <40>;
				qcom,mdss-dsi-qsync-min-fps-2 = <60>;
				oplus,fod-on-vblank = <0>;
				oplus,fod-off-vblank = <0>;
				oplus,ofp-need-to-filter-backlight-dim-icon;
				qcom,mdss-dsi-bl-demura1-command = [
					/* 51hex > 0x644 */
					39 00 00 50 00 00 06 F0 55 AA 52 08 04
					39 00 00 50 00 00 02 6F 02
					39 00 00 50 00 00 03 EC 01 03
					39 00 00 50 00 00 02 6F A5
					39 00 00 10 00 00 07 EC 01 01 01 03 03 03
				];
				qcom,mdss-dsi-bl-demura2-command = [
					/* 0x644>51hex>=0x530 */
					39 00 00 50 00 00 06 F0 55 AA 52 08 04
					39 00 00 50 00 00 02 6F 02
					39 00 00 50 00 00 03 EC 03 0B
					39 00 00 50 00 00 02 6F A5
					39 00 00 10 00 00 07 EC 03 03 03 0B 0B 0B
				];
				qcom,mdss-dsi-bl-demura3-command = [
					/* 0x530>51hex>=0x33A */
					39 00 00 50 00 00 06 F0 55 AA 52 08 04
					39 00 00 50 00 00 02 6F 02
					39 00 00 50 00 00 03 EC 10 18
					39 00 00 50 00 00 02 6F A5
					39 00 00 10 00 00 07 EC 10 10 10 18 18 18
				];
				qcom,mdss-dsi-bl-demura4-command = [
					/* 0x339>51hex>=0x25C */
					39 00 00 50 00 00 06 F0 55 AA 52 08 04
					39 00 00 50 00 00 02 6F 02
					39 00 00 50 00 00 03 EC 15 1D
					39 00 00 50 00 00 02 6F A5
					39 00 00 10 00 00 07 EC 15 15 15 1D 1D 1D
				];
				qcom,mdss-dsi-bl-demura5-command = [
					/* 0x25C>51hex>=0x196 */
					39 00 00 50 00 00 06 F0 55 AA 52 08 04
					39 00 00 50 00 00 02 6F 02
					39 00 00 50 00 00 03 EC 15 2D
					39 00 00 50 00 00 02 6F A5
					39 00 00 10 00 00 07 EC 15 15 15 2D 2D 2D
				];
				qcom,mdss-dsi-bl-demura6-command = [
					/* 0x196>51hex>=0x008 */
					39 00 00 50 00 00 06 F0 55 AA 52 08 04
					39 00 00 50 00 00 02 6F 02
					39 00 00 50 00 00 03 EC 15 4D
					39 00 00 50 00 00 02 6F A5
					39 00 00 10 00 00 07 EC 15 15 15 4D 4D 4D
				];
				qcom,mdss-dsi-skipframe-dbv-command = [
					39 00 00 40 00 00 06 F0 55 AA 52 08 01
					39 00 00 40 00 00 02 6F 02
					39 00 00 40 00 00 11 E5 00 00 00 00 00 00 00 00 00 00 00 00 00 00 00 00
					39 00 00 40 00 00 02 6F 24
					39 00 00 40 00 00 0D E5 00 00 00 00 00 00 00 00 00 00 00 00
					39 00 00 40 00 00 02 6F 46
					39 00 00 40 00 00 0D E5 00 00 00 00 00 00 00 00 00 00 00 00
					39 00 00 40 00 00 02 6F 03
					39 00 00 40 00 00 19 C6 16 16 1F 23 23 23 23 23 23 23 23 21 23 23 23 23 23 23 18 18 21 23 23 23
					39 00 00 40 00 00 02 E5 B2
					39 00 00 40 00 00 02 6F 22
					39 00 00 40 00 00 02 E5 B2
					39 00 00 40 00 00 02 6F 44
					39 00 00 40 00 00 02 E5 B2
					39 00 00 40 00 00 06 F0 55 AA 52 08 05
					39 00 00 40 00 00 02 6F 12
					39 00 00 40 00 00 05 EC 00 00 00 00
					39 00 00 40 00 00 06 F0 55 AA 52 08 00
					39 00 00 40 00 00 02 6F 11
					39 00 00 40 00 00 04 B2 02 03 42
					39 00 00 00 00 00 03 51 03 FF
					];
				qcom,mdss-dsi-timing-switch-command = [
					/* switch */
					39 00 00 40 00 00 06 F0 55 AA 52 08 00
					39 00 00 00 0C 00 02 2F 00
					39 00 00 40 00 00 02 BE 5F
					39 00 00 40 00 00 02 6F A8
					39 00 00 40 00 00 03 BA 00 00
					39 00 00 40 00 00 02 6F B0
					39 00 00 40 00 00 05 BA 00 00 00 00
					39 00 00 40 00 00 02 2F 30
					39 00 00 40 00 00 02 6D 00
					39 00 00 00 00 00 05 35 00 00 00 00
					];
				qcom,mdss-dsi-on-command=[
					/*Skip frame*/
					39 00 00 40 00 00 06 F0 55 AA 52 08 00
					39 00 00 40 00 00 02 6F 1B
					39 00 00 40 00 00 02 BA 18
					39 00 00 40 00 00 02 6F 1C
					39 00 00 40 00 00 11 BA 01 01 01 01 00 01 02 03 00 01 02 03 00 00 00 00
					39 00 00 40 00 00 02 6F 2C
					39 00 00 40 00 00 11 BA 01 01 01 01 00 01 02 03 00 01 02 03 00 00 00 00
					39 00 00 40 00 00 02 6F 3C
					39 00 00 40 00 00 11 BA 01 01 01 01 00 01 02 03 00 01 02 03 00 00 00 00
					39 00 00 40 00 00 02 6F 4C
					39 00 00 40 00 00 11 BA 01 01 01 01 00 01 02 03 00 01 02 03 00 00 00 00
					39 00 00 40 00 00 02 6F 5C
					39 00 00 40 00 00 05 BA 01 01 01 01
					39 00 00 40 00 00 02 6F 6C
					39 00 00 40 00 00 05 BA 00 01 02 03
					39 00 00 40 00 00 02 6F 7C
					39 00 00 40 00 00 05 BA 00 01 02 03
					39 00 00 40 00 00 02 6F 8C
					39 00 00 40 00 00 05 BA 00 00 00 00
					39 00 00 40 00 00 02 6F 9C
					39 00 00 40 00 00 09 BA 11 11 11 11 11 11 11 11
					39 00 00 40 00 00 02 6F A4
					39 00 00 40 00 00 03 BA E4 E4
					39 00 00 40 00 00 02 6F A8
					39 00 00 40 00 00 04 BA 00 00 00
					39 00 00 40 00 00 02 6F B0
					39 00 00 40 00 00 05 BA 00 00 00 00
					39 00 00 40 00 00 02 6F 08
					39 00 00 40 00 00 17 BB 01 00 00 00 01 00 00 00 01 00 00 00 01 00 00 00 01 00 00 00 00 00
					39 00 00 40 00 00 06 F0 55 AA 52 08 01
					39 00 00 40 00 00 13 E5 B2 22 00 00 00 00 20 20 20 20 24 24 24 24 00 00 00 00
					39 00 00 40 00 00 02 6F 22
					39 00 00 40 00 00 13 E5 B2 22 00 00 00 00 20 20 20 20 24 24 24 24 00 00 00 00
					39 00 00 40 00 00 02 6F 44
					39 00 00 40 00 00 13 E5 B2 22 00 00 00 00 20 20 20 20 24 24 24 24 00 00 00 00
					39 00 00 40 00 00 02 6F 66
					39 00 00 40 00 00 13 E5 B2 22 00 00 00 00 20 20 20 20 24 24 24 24 00 00 00 00
					39 00 00 40 00 00 02 6F 0C
					39 00 00 40 00 00 03 CE 0D 11
					39 00 00 40 00 00 02 6F 27
					39 00 00 40 00 00 06 B9 AA AA AA 00 00
					39 00 00 40 00 00 02 6F 03
					39 00 00 40 00 00 07 C6 16 16 16 23 23 23
					39 00 00 40 00 00 02 6F 0C
					39 00 00 40 00 00 07 C6 16 16 16 23 23 23
					39 00 00 40 00 00 02 6F 15
					39 00 00 40 00 00 07 C6 16 16 16 23 23 23
					39 00 00 40 00 00 02 6F 1E
					39 00 00 40 00 00 07 C6 16 16 16 23 23 23
					39 00 00 40 00 00 06 F0 55 AA 52 08 00
					39 00 00 40 00 00 02 6F 13
					39 00 00 40 00 00 02 C2 D8
					39 00 00 40 00 00 06 F0 55 AA 52 08 05
					39 00 00 40 00 00 02 6F 12
					39 00 00 40 00 00 05 EC 00 00 00 00
					/* Optimize edge green */
					/*39 00 00 40 00 00 06 F0 55 AA 52 08 07*/
					/*39 00 00 40 00 00 0E B4 C0 80 80 80 80 50 80 80 80 80 80 50 80*/
					/* Vsync Hsync output */
					39 00 00 40 00 00 06 F0 55 AA 52 08 00
					39 00 00 40 00 00 02 6F 02
					39 00 00 00 00 00 03 BE 49 4C
					/* AVDD=7.9 */
					/* 39 00 00 40 00 00 06 F0 55 AA 52 08 00 */
					/* 39 00 00 40 00 00 02 6F 07 */
					/* 39 00 00 40 00 00 02 B5 4E */
					/* HBM L0 glows green */
					39 00 00 40 00 00 02 B5 80
					39 00 00 40 00 00 02 6F 2C
					39 00 00 00 00 00 02 B5 03
					39 00 00 40 00 00 05 FF AA 55 A5 81
					39 00 00 40 00 00 02 6F 19
					39 00 00 40 00 00 02 FB 00
					39 00 00 40 00 00 02 6F 05
					39 00 00 40 00 00 02 FE 34
					39 00 00 40 00 00 05 FF AA 55 A5 80
					39 00 00 40 00 00 02 6F 1A
					39 00 00 40 00 00 02 F4 55
					39 00 00 40 00 00 05 FF AA 55 A5 83
					39 00 00 40 00 00 02 6F 12
					39 00 00 40 00 00 02 FE 41
					39 00 00 40 00 00 02 5F 00
					39 00 00 40 00 00 02 26 00
					39 00 00 40 00 00 02 26 00
					39 00 00 40 00 00 02 17 10
					39 00 00 40 00 00 05 2A 00 00 04 D7
					39 00 00 00 00 00 05 2B 00 00 0A D3
					/* Fre 120Hz */
					39 00 00 00 00 00 02 2F 00
					/* TE ON */
					39 00 00 40 00 00 02 35 00
					39 00 00 00 00 00 03 44 00 00
					/* Nor 51 */
					39 00 00 40 00 00 03 51 00 00
					39 00 00 00 00 00 02 6F 04
					/* AOD 51 */
					39 00 00 40 00 00 03 51 00 00
					39 00 00 40 00 00 02 53 20
					39 00 00 00 00 00 03 90 03 03
					/* 10bit DSC */
					39 00 00 40 00 00 13 91 AB 28 00 0C F2 00 02 85 01 0F 00 08 0A E9 07 5F 10 F0
					39 00 00 40 00 00 05 FF AA 55 A5 81
					39 00 00 40 00 00 02 6F 24
					39 00 00 40 00 00 15 FB 00 03 04 55 77 77 77 99 9D 00 00 06 88 9A BB BC DE EF F0 11
					39 00 00 40 00 00 05 FF AA 55 A5 81
					39 00 00 40 00 00 02 6F 0E
					39 00 00 40 00 00 02 F5 00
					39 00 00 40 00 00 05 FF AA 55 A5 80
					39 00 00 40 00 00 02 6F 0F
					39 00 00 40 00 00 02 FC 00
					39 00 00 40 00 00 02 6F 09
					39 00 00 40 00 00 03 FC FC F0
					39 00 00 40 00 00 05 FF AA 55 A5 80
					39 00 00 40 00 00 02 6F 0A
					39 00 00 40 00 00 04 F6 70 70 70
					39 00 00 40 00 00 02 6F 0E
					39 00 00 00 00 00 02 F6 60
					/* OSC start */
					39 00 00 40 00 00 05 FF AA 55 A5 80
					39 00 00 40 00 00 02 6F 11
					/* OSC2 145Mhz */
					39 00 00 40 00 00 03 F8 01 8E
					39 00 00 40 00 00 02 6F 2D
					/* OSC1 121.9Mhz */
					39 00 00 40 00 00 03 F8 00 FC
					39 00 00 40 00 00 02 6F 01
					39 00 00 40 00 00 02 1F 06
					39 00 00 40 00 00 05 FF AA 55 A5 81
					39 00 00 40 00 00 02 6F 1E
					39 00 00 00 00 00 02 FB 0F
					/* OSC end */
					39 00 00 40 00 00 05 FF AA 55 A5 83
					39 00 00 40 00 00 02 6F 12
					39 00 00 40 00 00 02 FE 41
					39 00 00 40 00 00 05 FF AA 55 A5 80
					39 00 00 40 00 00 02 6F 19
					39 00 00 40 00 00 02 F2 00
					39 00 00 40 00 00 05 FF AA 55 A5 81
					39 00 00 40 00 00 02 6F 02
					39 00 00 40 00 00 02 F9 04
					39 00 00 40 00 00 02 5A 00
					/* AOD remove black frame */
					39 00 00 00 00 00 06 F0 55 AA 52 08 01
					39 00 00 00 00 00 06 D2 00 00 00 00 15
					15 00 00 00 00 00 02 6F 05
					39 00 00 00 00 00 04 D2 01 00 00
					15 00 00 00 00 00 02 6F 0E
					39 00 00 00 00 00 06 D2 02 00 10 05 88
					39 00 00 00 00 00 0B E4 80 00 00 00 00 00 00 00 00 33
					15 00 00 00 00 00 02 6F 0A
					39 00 00 00 00 00 07 E4 80 00 00 10 00 53
					/* AOD off splash */
					39 00 00 40 00 00 06 F0 55 AA 52 08 01
					39 00 00 40 00 00 02 6F 0E
					39 00 00 00 00 00 06 D2 02 00 10 05 82
					/* 11H sleep out */
					39 00 00 00 80 00 02 11 00
					39 00 00 40 00 00 06 F0 55 AA 52 08 00
					39 00 00 00 11 00 02 2F 00
					39 00 00 40 00 00 02 BE 5F
					39 00 00 40 00 00 02 6F A8
					39 00 00 40 00 00 03 BA 00 00
					39 00 00 40 00 00 02 6F B0
					39 00 00 40 00 00 05 BA 00 00 00 00
					39 00 00 40 00 00 02 2F 30
					39 00 00 40 00 00 02 6D 00
					39 00 00 00 00 00 05 35 00 00 00 00
					05 00 00 00 00 00 01 29
					/* OSC Tracking for 60/90/120 fps */
					39 00 00 40 00 00 06 F0 55 AA 52 08 01
					39 00 00 00 11 00 2A C3 DD 06 22 15 F9 00 06 20 15 FF 00 03 E7 16 06 2B 1D 03 E7 16 06 2B 1D 03 E7 16 06 2B 1D 03 E7 16 06 2B 1D 03 E7 16 06 2B 1D
				];

				qcom,mdss-dsi-panel-info-switch-page-command = [
					/*read panel info switch page 01*/
					39 00 00 00 00 00 06 F0 55 AA 52 08 01
				];
				qcom,mdss-dsi-default-switch-page-command = [
					/*switch default page*/
					39 00 00 00 00 00 06 F0 55 AA 52 08 00
				];

				qcom,mdss-dsi-qsync-off-commands = [
					15 00 00 40 00 00 02 2F 00
					15 00 00 40 00 00 02 2F 30
					15 00 00 00 00 00 02 6D 00
				];
				qcom,mdss-dsi-qsync-min-fps-0-command = [
					/* SDC Auto Off */
					15 00 00 40 00 00 02 2F 00
					15 00 00 40 00 00 02 2F 30
					15 00 00 00 00 00 02 6D 03
				];
				qcom,mdss-dsi-qsync-min-fps-1-command = [
                    			/* SDC Auto Off */
                    			15 00 00 40 00 00 02 2F 00
                    			15 00 00 40 00 00 02 2F 30
                    			15 00 00 00 00 00 02 6D 02
                		];

				qcom,mdss-dsi-qsync-min-fps-2-command = [
                    			/* SDC Auto Off */
                    			15 00 00 40 00 00 02 2F 00
                    			15 00 00 40 00 00 02 2F 30
                    			15 00 00 00 00 00 02 6D 01
                		];

				qcom,mdss-dsi-post-on-backlight = [
					/* Display On */
					05 00 00 00 00 00 01 29
				];
				qcom,mdss-dsi-off-command=[
					05 00 00 00 0A 00 01 28
					05 00 00 00 78 00 01 10
				];
				qcom,mdss-dsi-lp1-command = [
					/* AOD Mode ON Setting */
					39 00 00 00 00 00 06 F0 55 AA 52 08 00
					15 00 00 00 00 00 02 6F 0C
					39 00 00 00 00 00 03 B5 50 4B
					39 00 00 00 00 00 05 35 00 00 00 00
					39 00 00 00 00 00 03 44 00 00
					15 00 00 00 00 00 02 2F 00
					05 00 00 00 00 00 01 39
					15 00 00 00 00 00 02 65 01
					15 00 00 00 00 00 02 6F 04
					39 00 00 00 00 00 03 51 02 FF
				];
				qcom,mdss-dsi-nolp-command = [
					/* AOD OFF */
					39 00 00 00 00 00 06 F0 55 AA 52 08 00
					15 00 00 00 00 00 02 6F 0C
					39 00 00 00 00 00 03 B5 4F 4B
					15 00 00 00 00 00 02 65 00
					05 00 00 00 00 00 01 38
					15 00 00 00 00 00 02 2F 30
					15 00 00 00 00 00 02 6D 00
					39 00 00 00 00 00 05 35 00 00 00 00
					39 00 00 00 00 00 03 44 00 00
					39 00 00 00 28 00 03 51 00 00
				];
				qcom,mdss-dsi-hbm-off-command = [
					//39 00 00 00 00 00 03 51 0D BB
				];
				qcom,mdss-dsi-hbm-on-command = [
					39 00 00 40 00 00 06 F0 55 AA 52 08 04
					39 00 00 40 00 00 02 6F 02
					39 00 00 40 00 00 03 EC 01 03
					39 00 00 40 00 00 02 6F A5
					39 00 00 00 00 00 07 EC 01 01 01 03 03 03
					39 00 00 40 00 00 06 F0 55 AA 52 08 01
					39 00 00 40 00 00 02 6F 02
					39 00 00 40 00 00 09 E5 00 00 00 00 20 20 20 00
					39 00 00 40 00 00 02 6F 46
					39 00 00 40 00 00 0D E5 00 00 00 00 20 20 20 00 28 28 28 00
					39 00 00 40 00 00 02 6F 03
					39 00 00 40 00 00 19 C6 37 37 37 23 23 23 23 23 23 23 23 23 23 23 23 23 23 23 37 37 37 23 23 23
					39 00 00 40 00 00 02 E5 B2
					39 00 00 40 00 00 02 6F 44
					39 00 00 40 00 00 02 E5 B2
					39 00 00 40 00 00 06 F0 55 AA 52 08 05
					39 00 00 40 00 00 02 6F 12
					39 00 00 40 00 00 05 EC 00 00 00 00
					39 00 00 40 00 00 06 F0 55 AA 52 08 00
					39 00 00 40 00 00 02 6F 11
					39 00 00 40 00 00 04 B2 02 03 42
					39 00 00 00 00 00 03 51 0F 00
				];
				qcom,mdss-dsi-aod-high-mode-command = [
					/* AOD 50nit */
					15 00 00 40 00 00 02 6F 04
					39 00 00 00 00 00 03 51 02 FF
				];
				qcom,mdss-dsi-aod-low-mode-command = [
					/* AOD 10nit */
					15 00 00 40 00 00 02 6F 04
					39 00 00 00 00 00 03 51 01 FF
				];
				qcom,mdss-dsi-aod-hbm-on-command-state = "dsi_hs_mode";
				qcom,mdss-dsi-aod-hbm-off-command-state = "dsi_hs_mode";
				qcom,mdss-dsi-timing-switch-command-state = "dsi_hs_mode";
				qcom,mdss-dsi-bl-16plus-command-state = "dsi_hs_mode";
				qcom,mdss-dsi-bl-3plus-command-state = "dsi_hs_mode";
				qcom,mdss-dsi-on-command-state = "dsi_lp_mode";
				qcom,mdss-dsi-off-command-state = "dsi_hs_mode";
				qcom,mdss-dsi-hbm-on-command-state = "dsi_hs_mode";
				qcom,mdss-dsi-hbm-off-command-state = "dsi_hs_mode";
				qcom,mdss-dsi-skipframe-dbv-command-state = "dsi_hs_mode";
				qcom,mdss-dsi-qsync-min-fps-0-command-state = "dsi_hs_mode";
				qcom,mdss-dsi-qsync-min-fps-1-command-state = "dsi_hs_mode";
				qcom,mdss-dsi-qsync-min-fps-2-command-state = "dsi_hs_mode";
				qcom,mdss-dsi-bl-demura1-command-state = "dsi_hs_mode";
				qcom,mdss-dsi-bl-demura2-command-state = "dsi_hs_mode";
				qcom,mdss-dsi-bl-demura3-command-state = "dsi_hs_mode";
				qcom,mdss-dsi-bl-demura4-command-state = "dsi_hs_mode";
				qcom,mdss-dsi-bl-demura5-command-state = "dsi_hs_mode";
				qcom,mdss-dsi-bl-demura6-command-state = "dsi_hs_mode";
				qcom,mdss-dsi-panel-info-switch-page-command-state = "dsi_lp_mode";
				qcom,mdss-dsi-default-switch-page-command-state = "dsi_lp_mode";

				qcom,lm-split = <620 620>;
				qcom,compression-mode = "dsc";
				qcom,mdss-dsc-encoders = <2>;
				qcom,mdss-dsc-slice-height = <12>;
				qcom,mdss-dsc-slice-width = <620>;
				qcom,mdss-dsc-slice-per-pkt = <2>;
				qcom,mdss-dsc-bit-per-component = <10>;
				qcom,mdss-dsc-bit-per-pixel = <8>;
				qcom,mdss-dsc-block-prediction-enable;
			};
		};
	};
};

&soc {
	dsi_oplus_zonda_sec_tianma_nt37705_1240_2772_dsc_cmd {
		qcom,dsi-display-active;
	};
};

&dsi_oplus_zonda_sec_tianma_nt37705_1240_2772_dsc_cmd {
	qcom,panel-supply-entries = <&oplus_zonda_dsi_panel_pwr_supply>;
	qcom,mdss-dsi-panel-controller = <&mdss_dsi0>;
	qcom,mdss-dsi-bl-pmic-control-type = "bl_ctrl_dcs";
	qcom,bl-update-flag = "delay_until_first_frame";
	qcom,mdss-dsi-bl-min-level = <1>;
	qcom,mdss-dsi-bl-max-level = <4095>;
	qcom,mdss-brightness-max-level = <4095>;
	oplus,dsi-bl-normal-max-level = <3515>;
	oplus,dsi-brightness-normal-max-level = <3515>;

	oplus,dsi-brightness-default-level = <1638>;
	qcom,mdss-dsi-bl-inverted-dbv;
	qcom,platform-te-gpio = <&tlmm 86 0>;
	qcom,dynamic-te-gpio = <&tlmm 23 0>;
	qcom,platform-reset-gpio = <&tlmm 3 0>;
	qcom,platform-panel-vout-gpio = <&tlmm 90 0>;

	qcom,ulps-enabled;
	qcom,dsi-select-clocks = "pll_byte_clk0", "pll_dsi_clk0";

	/* aod/fod config */
	oplus,ofp-fp-type = <0x08>;
	oplus,ofp-need-to-wait-data-before-aod-on;

	/* adfr config */
	/* just for qsync enable*/
	qcom,qsync-enable;
	qcom,mdss-dsi-qsync-min-refresh-rate = <24>;
	/*
	** 0st bit: adfr global on/off
	** 1st bit: fakeframe on/off
	** 2st bit: switch on/off
	** 3rd bit: 0:double-TE switch 1:external TE/TP switch
	** 4rd bit: idle mode on/off
	*/
	oplus,adfr-config = <0>;

	qcom,mdss-dsi-display-timings {
		timing@fhd_sdc_120 { /* FHD+ 120hz */
			qcom,mdss-dsi-panel-phy-timings = [00 2C 0C 0C 1D 1A 0C 0C 0B 02 04 00 24 11];
			qcom,display-topology = <1 1 1>,<2 2 1>;
			qcom,default-topology-index = <1>;
		};
		timing@fhd_sdc_90 { /* FHD+ 90hz */
			qcom,mdss-dsi-panel-phy-timings = [00 2C 0C 0C 1D 1A 0C 0C 0B 02 04 00 24 11];
			qcom,display-topology = <1 1 1>,<2 2 1>;
			qcom,default-topology-index = <1>;
		};
		timing@fhd_sdc_60 { /* FHD+ 60hz */
			qcom,mdss-dsi-panel-phy-timings = [00 2C 0C 0C 1D 1A 0C 0C 0B 02 04 00 24 11];
			qcom,display-topology = <1 1 1>,<2 2 1>;
			qcom,default-topology-index = <1>;
		};
		timing@fhd_sdc_144 { /* FHD+ 144hz */
			qcom,mdss-dsi-panel-phy-timings = [00 2C 0C 0C 1D 1A 0C 0C 0B 02 04 00 24 11];
			qcom,display-topology = <1 1 1>,<2 2 1>;
			qcom,default-topology-index = <1>;
		};
		timing@fhd_oplus_120 { /* FHD+ 120hz */
			qcom,mdss-dsi-panel-phy-timings = [00 2C 0C 0C 1D 1A 0C 0C 0B 02 04 00 24 11];
			qcom,display-topology = <1 1 1>,<2 2 1>;
			qcom,default-topology-index = <1>;
		};
	};
};
&dsi_oplus_zonda_sec_tianma_nt37705_1240_2772_dsc_cmd {
	oplus,color_vivid_status;
	oplus,color_srgb_status;
	oplus,color_softiris_status;
	oplus,color_dual_brightness_status;
	//oplus,color_oplus_calibrate_status;
	//oplus,apollo_backlight_enable;
	//oplus,color_srgb_status;
	oplus,dsi-serial-number-enabled;
	//oplus,dsi-serial-number-lock;
	oplus,dsi-serial-number-switch-page;
	oplus,dsi-serial-number-index= <0>;
	oplus,dsi-serial-number-reg= <0xD7>;
	oplus,dsi-serial-number-read-count= <7>;
	oplus,enhance_mipi_strength;
	oplus,sw_reset_ctrl_flag;
	oplus,disp_hw_seq_modify_flag;
	oplus,gpio-pre-on;
};
&dsi_oplus_zonda_sec_tianma_nt37705_1240_2772_dsc_cmd {
	qcom,panel_voltage_vddi_name = "vddio";
	qcom,panel_voltage_vddi = <0 1800000 1850000 1950000>;
	qcom,panel_voltage_vddr_name = "vddio";
	qcom,panel_voltage_vddr = <1 1800000 1850000 1950000>;
};

/* #ifdef OPLUS_FEATURE_DISPLAY */
&mdss_dsi_phy0 {
	oplus,dsi-pll-ssc-disalbed;
};

&mdss_dsi_phy1 {
	oplus,dsi-pll-ssc-disalbed;
};
/* OPLUS_FEATURE_DISPLAY */
